[part 1 of 12: packages /VehicleProject/ECU to /E40_Platform_System_SystemPackage/Components]
AUTOSAR XML (schema 4-2-1)
standard types defined: uint8, uint16, UInt16, uint32, UInt32, sint32, boolean, Boolean, SInt32, UInt8, sint8, SInt8, sint16, SInt16
package /VehicleProject/ECU
  ecu instance IC
package /E40_Platform_System_SystemPackage
  composition sw component type E40_Platform_System_SoftwareArchitecture
    component E40_Platform_SystemCmp: type=E40_Platform_System
  system E40_Platform_System_System
    system mapping MAPPING
      sw-impl-mappings:
        64 x swc to impl mapping:
          ImplementationMapping1: component-implementation=IMPL_CBacklightCdd, component=SoftwareArchitecture.E40_Platform_SystemCmp.CBacklightCdd
          ImplementationMapping2: component-implementation=IMPL_IoHwAb, component=SoftwareArchitecture.E40_Platform_SystemCmp.IoHwAb
          ImplementationMapping3: component-implementation=IMPL_CCDD_BswFit, component=SoftwareArchitecture.E40_Platform_SystemCmp.CCDD_BswFit
          ImplementationMapping4: component-implementation=IMPL_EcuMExt, component=SoftwareArchitecture.E40_Platform_SystemCmp.EcuMExt
          ImplementationMapping5: component-implementation=IMPL_EcuAppM, component=SoftwareArchitecture.E40_Platform_SystemCmp.EcuAppM
          ImplementationMapping6: component-implementation=IMPL_CCDD_EcuBatteryM, component=SoftwareArchitecture.E40_Platform_SystemCmp.CCDD_EcuBatteryM
          ImplementationMapping7: component-implementation=IMPL_CCDD_EcuPowerM, component=SoftwareArchitecture.E40_Platform_SystemCmp.CCDD_EcuPowerM
          ImplementationMapping8: component-implementation=IMPL_CComAbsCtrl, component=SoftwareArchitecture.E40_Platform_SystemCmp.CComAbsCtrl
          ImplementationMapping9: component-implementation=IMPL_ComMExt, component=SoftwareArchitecture.E40_Platform_SystemCmp.ComMExt
          ImplementationMapping10: component-implementation=IMPL_CComAbsMdl, component=SoftwareArchitecture.E40_Platform_SystemCmp.CComAbsMdl
          ImplementationMapping11: component-implementation=IMPL_MemAbstractMdl, component=SoftwareArchitecture.E40_Platform_SystemCmp.MemAbstractMdl
          ImplementationMapping12: component-implementation=IMPL_CComAbsMdlSafe, component=SoftwareArchitecture.E40_Platform_SystemCmp.CComAbsMdlSafe
          ImplementationMapping13: component-implementation=IMPL_Ctrl_Illumination, component=SoftwareArchitecture.E40_Platform_SystemCmp.Ctrl_Illumination
          ImplementationMapping14: component-implementation=IMPL_Mdl_Dim, component=SoftwareArchitecture.E40_Platform_SystemCmp.Mdl_Dim
          ImplementationMapping15: component-implementation=IMPL_Ctrl_WSS, component=SoftwareArchitecture.E40_Platform_SystemCmp.Ctrl_WSS
          ImplementationMapping16: component-implementation=IMPL_NvMExt, component=SoftwareArchitecture.E40_Platform_SystemCmp.NvMExt
          ImplementationMapping17: component-implementation=IMPL_TmExt, component=SoftwareArchitecture.E40_Platform_SystemCmp.TmExt
          ImplementationMapping18: component-implementation=IMPL_CWarnMsg_Core_Observer, component=SoftwareArchitecture.E40_Platform_SystemCmp.CWarnMsg_Core_Observer
          ImplementationMapping19: component-implementation=IMPL_Ctrl_warning, component=SoftwareArchitecture.E40_Platform_SystemCmp.Ctrl_warning
          ImplementationMapping20: component-implementation=IMPL_UclProxyCdd, component=SoftwareArchitecture.E40_Platform_SystemCmp.UclProxyCdd
          ImplementationMapping21: component-implementation=IMPL_DmnMgr, component=SoftwareArchitecture.E40_Platform_SystemCmp.DmnMgr
          ImplementationMapping22: component-implementation=IMPL_CMeetCdd, component=SoftwareArchitecture.E40_Platform_SystemCmp.CMeetCdd
          ImplementationMapping23: component-implementation=IMPL_Mdl_Gear, component=SoftwareArchitecture.E40_Platform_SystemCmp.Mdl_Gear
          ImplementationMapping24: component-implementation=IMPL_View_Illumination, component=SoftwareArchitecture.E40_Platform_SystemCmp.View_Illumination
          ImplementationMapping25: component-implementation=IMPL_CView_Telltale, component=SoftwareArchitecture.E40_Platform_SystemCmp.CView_Telltale
          ImplementationMapping26: component-implementation=IMPL_Mdl_Airbag, component=SoftwareArchitecture.E40_Platform_SystemCmp.Mdl_Airbag
          ImplementationMapping27: component-implementation=IMPL_Mdl_TurnHazard, component=SoftwareArchitecture.E40_Platform_SystemCmp.Mdl_TurnHazard
          ImplementationMapping28: component-implementation=IMPL_CCtrl_Telltale, component=SoftwareArchitecture.E40_Platform_SystemCmp.CCtrl_Telltale
          ImplementationMapping29: component-implementation=IMPL_FastGaugeAdapter, component=SoftwareArchitecture.E40_Platform_SystemCmp.FastGaugeAdapter
          ImplementationMapping30: component-implementation=IMPL_View_Speed, component=SoftwareArchitecture.E40_Platform_SystemCmp.View_Speed
          ImplementationMapping31: component-implementation=IMPL_Mdl_Speed, component=SoftwareArchitecture.E40_Platform_SystemCmp.Mdl_Speed
          ImplementationMapping32: component-implementation=IMPL_Mdl_Linear_Interpolation, component=SoftwareArchitecture.E40_Platform_SystemCmp.Mdl_Linear_Interpolation
          ImplementationMapping33: component-implementation=IMPL_Mdl_Tacho, component=SoftwareArchitecture.E40_Platform_SystemCmp.Mdl_Tacho
          ImplementationMapping34: component-implementation=IMPL_SlowGaugeAdapter, component=SoftwareArchitecture.E40_Platform_SystemCmp.SlowGaugeAdapter
          ImplementationMapping35: component-implementation=IMPL_CUpdateCdd, component=SoftwareArchitecture.E40_Platform_SystemCmp.CUpdateCdd
          ImplementationMapping36: component-implementation=IMPL_DltExt, component=SoftwareArchitecture.E40_Platform_SystemCmp.DltExt
          ImplementationMapping37: component-implementation=IMPL_Mdl_wAirbag, component=SoftwareArchitecture.E40_Platform_SystemCmp.Mdl_wAirbag
          ImplementationMapping38: component-implementation=IMPL_Mdl_wFuelLidOpen, component=SoftwareArchitecture.E40_Platform_SystemCmp.Mdl_wFuelLidOpen
          ImplementationMapping39: component-implementation=IMPL_WarnMsg_Core_TmrSupport, component=SoftwareArchitecture.E40_Platform_SystemCmp.WarnMsg_Core_TmrSupport
          ImplementationMapping40: component-implementation=IMPL_DcmApp, component=SoftwareArchitecture.E40_Platform_SystemCmp.DcmApp
          ImplementationMapping41: component-implementation=IMPL_DemApp, component=SoftwareArchitecture.E40_Platform_SystemCmp.DemApp
          ImplementationMapping42: component-implementation=IMPL_DemExt, component=SoftwareArchitecture.E40_Platform_SystemCmp.DemExt
          ImplementationMapping43: component-implementation=IMPL_CDisplayCdd, component=SoftwareArchitecture.E40_Platform_SystemCmp.CDisplayCdd
          ImplementationMapping44: component-implementation=IMPL_CFltM, component=SoftwareArchitecture.E40_Platform_SystemCmp.CFltM
          ImplementationMapping45: component-implementation=IMPL_CRstM, component=SoftwareArchitecture.E40_Platform_SystemCmp.CRstM
          ImplementationMapping46: component-implementation=IMPL_Dlt, component=SoftwareArchitecture.E40_Platform_SystemCmp.Dlt
          ImplementationMapping47: component-implementation=IMPL_CFltMExt, component=SoftwareArchitecture.E40_Platform_SystemCmp.CFltMExt
          ImplementationMapping48: component-implementation=IMPL_GdtCdd, component=SoftwareArchitecture.E40_Platform_SystemCmp.GdtCdd
          ImplementationMapping49: component-implementation=IMPL_CIoExp, component=SoftwareArchitecture.E40_Platform_SystemCmp.CIoExp
          ImplementationMapping50: component-implementation=IMPL_CPmicCdd, component=SoftwareArchitecture.E40_Platform_SystemCmp.CPmicCdd
          ImplementationMapping51: component-implementation=IMPL_RtcCdd, component=SoftwareArchitecture.E40_Platform_SystemCmp.RtcCdd
          ImplementationMapping52: component-implementation=IMPL_SafeNvM, component=SoftwareArchitecture.E40_Platform_SystemCmp.SafeNvM
          ImplementationMapping53: component-implementation=IMPL_CSigCdd, component=SoftwareArchitecture.E40_Platform_SystemCmp.CSigCdd
          ImplementationMapping54: component-implementation=IMPL_CSwcDispMonSf, component=SoftwareArchitecture.E40_Platform_SystemCmp.CSwcDispMonSf
          ImplementationMapping55: component-implementation=IMPL_CSndCdd, component=SoftwareArchitecture.E40_Platform_SystemCmp.CSndCdd
          ImplementationMapping56: component-implementation=IMPL_CorTst, component=SoftwareArchitecture.E40_Platform_SystemCmp.CorTst
          ImplementationMapping57: component-implementation=IMPL_FlsTst, component=SoftwareArchitecture.E40_Platform_SystemCmp.FlsTst
          ImplementationMapping58: component-implementation=IMPL_RamTst, component=SoftwareArchitecture.E40_Platform_SystemCmp.RamTst
          ImplementationMapping59: component-implementation=IMPL_SysTst, component=SoftwareArchitecture.E40_Platform_SystemCmp.SysTst
          ImplementationMapping60: component-implementation=IMPL_CCDD_FitManager, component=SoftwareArchitecture.E40_Platform_SystemCmp.CCDD_FitManager
          ImplementationMapping61: component-implementation=IMPL_CCDD_McuFit, component=SoftwareArchitecture.E40_Platform_SystemCmp.CCDD_McuFit
          ImplementationMapping62: component-implementation=IMPL_ComCallout, component=SoftwareArchitecture.E40_Platform_SystemCmp.ComCallout
          ImplementationMapping63: component-implementation=IMPL_DcmExt, component=SoftwareArchitecture.E40_Platform_SystemCmp.DcmExt
          ImplementationMapping64: component-implementation=IMPL_Mdl_SafetyAdapter, component=SoftwareArchitecture.E40_Platform_SystemCmp.Mdl_SafetyAdapter
      sw-mappings:
        swc to ecu mapping SwcToEcuMapping: ecu-instance=IC
    root-software-compositions:
      root sw composition prototype SoftwareArchitecture: software-composition=E40_Platform_System
package /E40_Platform_System_SystemPackage/Components
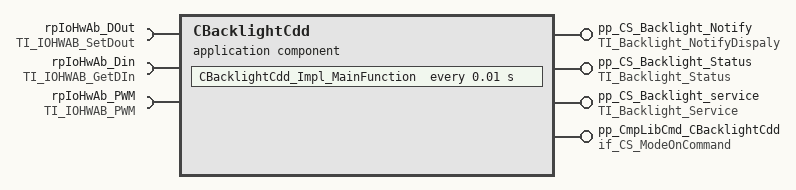
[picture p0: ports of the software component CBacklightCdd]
  application sw component type CBacklightCdd
    4 x provide port:
      pp_CS_Backlight_Notify: server-com-spec{operation=NotifyDisplayPowerState, queue-length=1}, provided-interface=TI_Backlight_NotifyDispaly
      pp_CS_Backlight_Status: server-com-spec{operation=TI_Backlight_Status/GetStatus, queue-length=1}, provided-interface=TI_Backlight_Status
      pp_CS_Backlight_service: provided-interface=TI_Backlight_Service
        provided-com-specs:
          operation=GetBrightnessValue, queue-length=1
          operation=GetThermalValue, queue-length=1
          operation=SetBrightnessValue, queue-length=1
      pp_CmpLibCmd_CBacklightCdd: server-com-spec{operation=Impl_OnCommand, queue-length=1}, provided-interface=if_CS_ModeOnCommand
    require port rpIoHwAb_DOut: required-interface=TI_IOHWAB_SetDout
    require port rpIoHwAb_Din: required-interface=TI_IOHWAB_GetDIn
    require port rpIoHwAb_PWM: required-interface=TI_IOHWAB_PWM
    behavior IB_CBacklightCdd
      operation invoked event OIE_pp_CS_Backlight_service_CBacklightCdd_GetBrightnessValueTrigByGetBrightnessValue: start-on-event=CBacklightCdd_GetBrightnessValue, operation=pp_CS_Backlight_service.GetBrightnessValue
      operation invoked event OIE_pp_CS_Backlight_Status_CBacklightCdd_GetStatusTrigByGetStatus: start-on-event=CBacklightCdd_GetStatus, operation=pp_CS_Backlight_Status.GetStatus
      operation invoked event OIE_pp_CS_Backlight_service_CBacklightCdd_GetThermalValueTrigByGetThermalValue: start-on-event=CBacklightCdd_GetThermalValue, operation=pp_CS_Backlight_service.GetThermalValue
      timing event TECBacklightCdd_Impl_MainFunction: start-on-event=CBacklightCdd_Impl_MainFunction, period=0.01
      operation invoked event OIE_pp_CmpLibCmd_CBacklightCdd_CBacklightCdd_Impl_OnCommandTrigByImpl_OnCommand: start-on-event=CBacklightCdd_Impl_OnCommand, operation=pp_CmpLibCmd_CBacklightCdd.Impl_OnCommand
      operation invoked event OIE_pp_CS_Backlight_Notify_CBacklightCdd_NotifyDisplayPowerStateTrigByNotifyDisplayPowerState: start-on-event=CBacklightCdd_NotifyDisplayPowerState, operation=pp_CS_Backlight_Notify.NotifyDisplayPowerState
      operation invoked event OIE_pp_CS_Backlight_service_CBacklightCdd_SetBrightnessValueTrigBySetBrightnessValue: start-on-event=CBacklightCdd_SetBrightnessValue, operation=pp_CS_Backlight_service.SetBrightnessValue
      port-api-options:
        enable-take-address=false, indirect-api=false, port=pp_CS_Backlight_Notify
        enable-take-address=false, indirect-api=false, port=pp_CS_Backlight_Status
        enable-take-address=false, indirect-api=false, port=pp_CS_Backlight_service
        enable-take-address=false, indirect-api=false, port=pp_CmpLibCmd_CBacklightCdd
        enable-take-address=false, indirect-api=false, port=CBacklightCdd/rpIoHwAb_DOut
        enable-take-address=false, indirect-api=false, port=CBacklightCdd/rpIoHwAb_Din
        enable-take-address=false, indirect-api=false, port=CBacklightCdd/rpIoHwAb_PWM
      7 x runnable, all with can-be-invoked-concurrently=true:
        CBacklightCdd_GetBrightnessValue
          9 x sync call, all with timeout=0.0:
            OA_rpIoHwAb_DOut_SetOutputGroup: operation=rpIoHwAb_DOut.SetOutputGroup
            OA_rpIoHwAb_DOut_SetOutputPin: operation=rpIoHwAb_DOut.SetOutputPin
            OA_rpIoHwAb_Din_GetAsyncRawInput: operation=rpIoHwAb_Din.GetAsyncRawInput
            OA_rpIoHwAb_Din_GetProcessedInput: operation=rpIoHwAb_Din.GetProcessedInput
            OA_rpIoHwAb_Din_GetSyncRawInput: operation=rpIoHwAb_Din.GetSyncRawInput
            OA_rpIoHwAb_Din_GetInputGroup: operation=rpIoHwAb_Din.GetInputGroup
            OA_rpIoHwAb_PWM_PwmSetDuty: operation=rpIoHwAb_PWM.PwmSetDuty
            OA_rpIoHwAb_PWM_PwmSetDutyAndPeriod: operation=rpIoHwAb_PWM.PwmSetDutyAndPeriod
            OA_rpIoHwAb_PWM_PwmSetIdeal: operation=rpIoHwAb_PWM.PwmSetIdeal
        CBacklightCdd_GetStatus
          9 x sync call, all with timeout=0.0:
            OA_rpIoHwAb_DOut_SetOutputGroup: operation=rpIoHwAb_DOut.SetOutputGroup
            OA_rpIoHwAb_DOut_SetOutputPin: operation=rpIoHwAb_DOut.SetOutputPin
            OA_rpIoHwAb_Din_GetAsyncRawInput: operation=rpIoHwAb_Din.GetAsyncRawInput
            OA_rpIoHwAb_Din_GetProcessedInput: operation=rpIoHwAb_Din.GetProcessedInput
            OA_rpIoHwAb_Din_GetSyncRawInput: operation=rpIoHwAb_Din.GetSyncRawInput
            OA_rpIoHwAb_Din_GetInputGroup: operation=rpIoHwAb_Din.GetInputGroup
            OA_rpIoHwAb_PWM_PwmSetDuty: operation=rpIoHwAb_PWM.PwmSetDuty
            OA_rpIoHwAb_PWM_PwmSetDutyAndPeriod: operation=rpIoHwAb_PWM.PwmSetDutyAndPeriod
            OA_rpIoHwAb_PWM_PwmSetIdeal: operation=rpIoHwAb_PWM.PwmSetIdeal
        CBacklightCdd_GetThermalValue
          9 x sync call, all with timeout=0.0:
            OA_rpIoHwAb_DOut_SetOutputGroup: operation=rpIoHwAb_DOut.SetOutputGroup
            OA_rpIoHwAb_DOut_SetOutputPin: operation=rpIoHwAb_DOut.SetOutputPin
            OA_rpIoHwAb_Din_GetAsyncRawInput: operation=rpIoHwAb_Din.GetAsyncRawInput
            OA_rpIoHwAb_Din_GetProcessedInput: operation=rpIoHwAb_Din.GetProcessedInput
            OA_rpIoHwAb_Din_GetSyncRawInput: operation=rpIoHwAb_Din.GetSyncRawInput
            OA_rpIoHwAb_Din_GetInputGroup: operation=rpIoHwAb_Din.GetInputGroup
            OA_rpIoHwAb_PWM_PwmSetDuty: operation=rpIoHwAb_PWM.PwmSetDuty
            OA_rpIoHwAb_PWM_PwmSetDutyAndPeriod: operation=rpIoHwAb_PWM.PwmSetDutyAndPeriod
            OA_rpIoHwAb_PWM_PwmSetIdeal: operation=rpIoHwAb_PWM.PwmSetIdeal
        CBacklightCdd_Impl_MainFunction
          9 x sync call, all with timeout=0.0:
            OA_rpIoHwAb_DOut_SetOutputGroup: operation=rpIoHwAb_DOut.SetOutputGroup
            OA_rpIoHwAb_DOut_SetOutputPin: operation=rpIoHwAb_DOut.SetOutputPin
            OA_rpIoHwAb_Din_GetAsyncRawInput: operation=rpIoHwAb_Din.GetAsyncRawInput
            OA_rpIoHwAb_Din_GetProcessedInput: operation=rpIoHwAb_Din.GetProcessedInput
            OA_rpIoHwAb_Din_GetSyncRawInput: operation=rpIoHwAb_Din.GetSyncRawInput
            OA_rpIoHwAb_Din_GetInputGroup: operation=rpIoHwAb_Din.GetInputGroup
            OA_rpIoHwAb_PWM_PwmSetDuty: operation=rpIoHwAb_PWM.PwmSetDuty
            OA_rpIoHwAb_PWM_PwmSetDutyAndPeriod: operation=rpIoHwAb_PWM.PwmSetDutyAndPeriod
            OA_rpIoHwAb_PWM_PwmSetIdeal: operation=rpIoHwAb_PWM.PwmSetIdeal
        CBacklightCdd_Impl_OnCommand
          9 x sync call, all with timeout=0.0:
            OA_rpIoHwAb_DOut_SetOutputGroup: operation=rpIoHwAb_DOut.SetOutputGroup
            OA_rpIoHwAb_DOut_SetOutputPin: operation=rpIoHwAb_DOut.SetOutputPin
            OA_rpIoHwAb_Din_GetAsyncRawInput: operation=rpIoHwAb_Din.GetAsyncRawInput
            OA_rpIoHwAb_Din_GetProcessedInput: operation=rpIoHwAb_Din.GetProcessedInput
            OA_rpIoHwAb_Din_GetSyncRawInput: operation=rpIoHwAb_Din.GetSyncRawInput
            OA_rpIoHwAb_Din_GetInputGroup: operation=rpIoHwAb_Din.GetInputGroup
            OA_rpIoHwAb_PWM_PwmSetDuty: operation=rpIoHwAb_PWM.PwmSetDuty
            OA_rpIoHwAb_PWM_PwmSetDutyAndPeriod: operation=rpIoHwAb_PWM.PwmSetDutyAndPeriod
            OA_rpIoHwAb_PWM_PwmSetIdeal: operation=rpIoHwAb_PWM.PwmSetIdeal
        CBacklightCdd_NotifyDisplayPowerState
          9 x sync call, all with timeout=0.0:
            OA_rpIoHwAb_DOut_SetOutputGroup: operation=rpIoHwAb_DOut.SetOutputGroup
            OA_rpIoHwAb_DOut_SetOutputPin: operation=rpIoHwAb_DOut.SetOutputPin
            OA_rpIoHwAb_Din_GetAsyncRawInput: operation=rpIoHwAb_Din.GetAsyncRawInput
            OA_rpIoHwAb_Din_GetProcessedInput: operation=rpIoHwAb_Din.GetProcessedInput
            OA_rpIoHwAb_Din_GetSyncRawInput: operation=rpIoHwAb_Din.GetSyncRawInput
            OA_rpIoHwAb_Din_GetInputGroup: operation=rpIoHwAb_Din.GetInputGroup
            OA_rpIoHwAb_PWM_PwmSetDuty: operation=rpIoHwAb_PWM.PwmSetDuty
            OA_rpIoHwAb_PWM_PwmSetDutyAndPeriod: operation=rpIoHwAb_PWM.PwmSetDutyAndPeriod
            OA_rpIoHwAb_PWM_PwmSetIdeal: operation=rpIoHwAb_PWM.PwmSetIdeal
        CBacklightCdd_SetBrightnessValue
          9 x sync call, all with timeout=0.0:
            OA_rpIoHwAb_DOut_SetOutputGroup: operation=rpIoHwAb_DOut.SetOutputGroup
            OA_rpIoHwAb_DOut_SetOutputPin: operation=rpIoHwAb_DOut.SetOutputPin
            OA_rpIoHwAb_Din_GetAsyncRawInput: operation=rpIoHwAb_Din.GetAsyncRawInput
            OA_rpIoHwAb_Din_GetProcessedInput: operation=rpIoHwAb_Din.GetProcessedInput
            OA_rpIoHwAb_Din_GetSyncRawInput: operation=rpIoHwAb_Din.GetSyncRawInput
            OA_rpIoHwAb_Din_GetInputGroup: operation=rpIoHwAb_Din.GetInputGroup
            OA_rpIoHwAb_PWM_PwmSetDuty: operation=rpIoHwAb_PWM.PwmSetDuty
            OA_rpIoHwAb_PWM_PwmSetDutyAndPeriod: operation=rpIoHwAb_PWM.PwmSetDutyAndPeriod
            OA_rpIoHwAb_PWM_PwmSetIdeal: operation=rpIoHwAb_PWM.PwmSetIdeal
  swc implementation IMPL_CBacklightCdd: programming-language=C, behavior=IB_CBacklightCdd
    code-descriptors:
      code CodeDescriptor
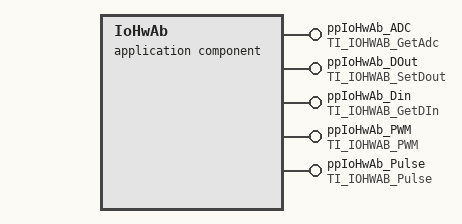
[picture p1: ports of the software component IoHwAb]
  application sw component type IoHwAb
    5 x provide port:
      ppIoHwAb_ADC: provided-interface=TI_IOHWAB_GetAdc
        provided-com-specs:
          operation=GetAsyncRawAdc, queue-length=1
          operation=GetProcessedAdc, queue-length=1
          operation=GetSyncRawAdc, queue-length=1
      ppIoHwAb_DOut: provided-com-specs=[{operation=SetOutputGroup, queue-length=1}, {operation=SetOutputPin, queue-length=1}], provided-interface=TI_IOHWAB_SetDout
      ppIoHwAb_Din: provided-interface=TI_IOHWAB_GetDIn
        provided-com-specs:
          operation=GetAsyncRawInput, queue-length=1
          operation=GetInputGroup, queue-length=1
          operation=GetProcessedInput, queue-length=1
          operation=GetSyncRawInput, queue-length=1
      ppIoHwAb_PWM: provided-interface=TI_IOHWAB_PWM
        provided-com-specs:
          operation=PwmSetDuty, queue-length=1
          operation=PwmSetDutyAndPeriod, queue-length=1
          operation=PwmSetIdeal, queue-length=1
      ppIoHwAb_Pulse: provided-interface=TI_IOHWAB_Pulse
        provided-com-specs:
          operation=GetCurrentSignalStatus_PulseInput, queue-length=1
          operation=GetCurrentSpeed_PulseInput, queue-length=1
          operation=GetRollingCount_PulseInput, queue-length=1
          operation=ResetRollingCount_PulseInput, queue-length=1
          operation=Start_Signal_Measurement_PulseInput, queue-length=1
          operation=Stop_Signal_Measurement_PulseInput, queue-length=1
          operation=Update_CalibParam_PulseInput, queue-length=1
    behavior IB_IoHwAb
      10 x operation invoked event:
        OIE_ppIoHwAb_ADC_IoHwAb_GetAsyncRawAdcTrigByGetAsyncRawAdc: start-on-event=IoHwAb_GetAsyncRawAdc, operation=ppIoHwAb_ADC.GetAsyncRawAdc
        OIE_ppIoHwAb_Din_IoHwAb_GetAsyncRawInputTrigByGetAsyncRawInput: start-on-event=IoHwAb_GetAsyncRawInput, operation=ppIoHwAb_Din.GetAsyncRawInput
        OIE_ppIoHwAb_Pulse_IoHwAb_GetCurrentSignalStatus_PulseInputTrigByGetCurrentSignalStatus_PulseInput: start-on-event=IoHwAb_GetCurrentSignalStatus_PulseInput, operation=ppIoHwAb_Pulse.GetCurrentSignalStatus_PulseInput
        OIE_ppIoHwAb_Pulse_IoHwAb_GetCurrentSpeed_PulseInputTrigByGetCurrentSpeed_PulseInput: start-on-event=IoHwAb_GetCurrentSpeed_PulseInput, operation=ppIoHwAb_Pulse.GetCurrentSpeed_PulseInput
        OIE_ppIoHwAb_Din_IoHwAb_GetInputGroupTrigByGetInputGroup: start-on-event=IoHwAb_GetInputGroup, operation=ppIoHwAb_Din.GetInputGroup
        OIE_ppIoHwAb_ADC_IoHwAb_GetProcessedAdcTrigByGetProcessedAdc: start-on-event=IoHwAb_GetProcessedAdc, operation=ppIoHwAb_ADC.GetProcessedAdc
        OIE_ppIoHwAb_Din_IoHwAb_GetProcessedInputTrigByGetProcessedInput: start-on-event=IoHwAb_GetProcessedInput, operation=ppIoHwAb_Din.GetProcessedInput
        OIE_ppIoHwAb_Pulse_IoHwAb_GetRollingCount_PulseInputTrigByGetRollingCount_PulseInput: start-on-event=IoHwAb_GetRollingCount_PulseInput, operation=ppIoHwAb_Pulse.GetRollingCount_PulseInput
        OIE_ppIoHwAb_ADC_IoHwAb_GetSyncRawAdcTrigByGetSyncRawAdc: start-on-event=IoHwAb_GetSyncRawAdc, operation=ppIoHwAb_ADC.GetSyncRawAdc
        OIE_ppIoHwAb_Din_IoHwAb_GetSyncRawInputTrigByGetSyncRawInput: start-on-event=IoHwAb_GetSyncRawInput, operation=ppIoHwAb_Din.GetSyncRawInput
      5 x timing event:
        TEIoHwAb_MainFunction: start-on-event=IoHwAb_MainFunction, period=0.01
        TEIoHwAb_OsTask_SafeBsw_Task_10ms: start-on-event=IoHwAb_OsTask_SafeBsw_Task_10ms, period=0.01
        TEIoHwAb_OsTask_SafeBsw_WdgM_CheckPoint_10ms: start-on-event=IoHwAb_OsTask_SafeBsw_WdgM_CheckPoint_10ms, period=0.01
        TEIoHwAb_OsTask_SafeBsw_WdgM_CheckPoint_20ms: start-on-event=IoHwAb_OsTask_SafeBsw_WdgM_CheckPoint_20ms, period=0.02
        TEIoHwAb_OsTask_SafeBsw_WdgM_CheckPoint_30ms: start-on-event=IoHwAb_OsTask_SafeBsw_WdgM_CheckPoint_30ms, period=0.03
      9 x operation invoked event:
        OIE_ppIoHwAb_PWM_IoHwAb_PwmSetDutyTrigByPwmSetDuty: start-on-event=IoHwAb_PwmSetDuty, operation=ppIoHwAb_PWM.PwmSetDuty
        OIE_ppIoHwAb_PWM_IoHwAb_PwmSetDutyAndPeriodTrigByPwmSetDutyAndPeriod: start-on-event=IoHwAb_PwmSetDutyAndPeriod, operation=ppIoHwAb_PWM.PwmSetDutyAndPeriod
        OIE_ppIoHwAb_PWM_IoHwAb_PwmSetIdealTrigByPwmSetIdeal: start-on-event=IoHwAb_PwmSetIdeal, operation=ppIoHwAb_PWM.PwmSetIdeal
        OIE_ppIoHwAb_Pulse_IoHwAb_ResetRollingCount_PulseInputTrigByResetRollingCount_PulseInput: start-on-event=IoHwAb_ResetRollingCount_PulseInput, operation=ppIoHwAb_Pulse.ResetRollingCount_PulseInput
        OIE_ppIoHwAb_DOut_IoHwAb_SetOutputGroupTrigBySetOutputGroup: start-on-event=IoHwAb_SetOutputGroup, operation=ppIoHwAb_DOut.SetOutputGroup
        OIE_ppIoHwAb_DOut_IoHwAb_SetOutputPinTrigBySetOutputPin: start-on-event=IoHwAb_SetOutputPin, operation=ppIoHwAb_DOut.SetOutputPin
        OIE_ppIoHwAb_Pulse_IoHwAb_Start_Signal_Measurement_PulseInputTrigByStart_Signal_Measurement_PulseInput: start-on-event=IoHwAb_Start_Signal_Measurement_PulseInput, operation=ppIoHwAb_Pulse.Start_Signal_Measurement_PulseInput
        OIE_ppIoHwAb_Pulse_IoHwAb_Stop_Signal_Measurement_PulseInputTrigByStop_Signal_Measurement_PulseInput: start-on-event=IoHwAb_Stop_Signal_Measurement_PulseInput, operation=ppIoHwAb_Pulse.Stop_Signal_Measurement_PulseInput
        OIE_ppIoHwAb_Pulse_IoHwAb_Update_CalibParam_PulseInputTrigByUpdate_CalibParam_PulseInput: start-on-event=IoHwAb_Update_CalibParam_PulseInput, operation=ppIoHwAb_Pulse.Update_CalibParam_PulseInput
      port-api-options:
        enable-take-address=false, indirect-api=false, port=ppIoHwAb_ADC
        enable-take-address=false, indirect-api=false, port=ppIoHwAb_DOut
        enable-take-address=false, indirect-api=false, port=ppIoHwAb_Din
        enable-take-address=false, indirect-api=false, port=ppIoHwAb_PWM
        enable-take-address=false, indirect-api=false, port=ppIoHwAb_Pulse
      24 x runnable, all with can-be-invoked-concurrently=true:
        IoHwAb_GetAsyncRawAdc
        IoHwAb_GetAsyncRawInput
        IoHwAb_GetCurrentSignalStatus_PulseInput
        IoHwAb_GetCurrentSpeed_PulseInput
        IoHwAb_GetInputGroup
        IoHwAb_GetProcessedAdc
        IoHwAb_GetProcessedInput
        IoHwAb_GetRollingCount_PulseInput
        IoHwAb_GetSyncRawAdc
        IoHwAb_GetSyncRawInput
        IoHwAb_MainFunction
        IoHwAb_OsTask_SafeBsw_Task_10ms
        IoHwAb_OsTask_SafeBsw_WdgM_CheckPoint_10ms
        IoHwAb_OsTask_SafeBsw_WdgM_CheckPoint_20ms
        IoHwAb_OsTask_SafeBsw_WdgM_CheckPoint_30ms
        IoHwAb_PwmSetDuty
        IoHwAb_PwmSetDutyAndPeriod
        IoHwAb_PwmSetIdeal
        IoHwAb_ResetRollingCount_PulseInput
        IoHwAb_SetOutputGroup
        IoHwAb_SetOutputPin
        IoHwAb_Start_Signal_Measurement_PulseInput
        IoHwAb_Stop_Signal_Measurement_PulseInput
        IoHwAb_Update_CalibParam_PulseInput
  swc implementation IMPL_IoHwAb: programming-language=C, behavior=IB_IoHwAb
    code-descriptors:
      code CodeDescriptor
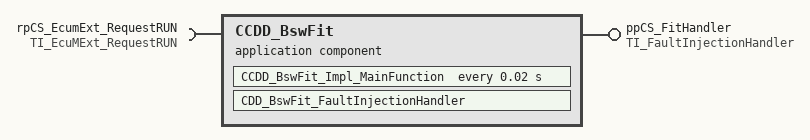
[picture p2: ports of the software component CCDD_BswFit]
  application sw component type CCDD_BswFit
    provide port ppCS_FitHandler: server-com-spec{operation=FaultInjectionHandler, queue-length=1}, provided-interface=TI_FaultInjectionHandler
    require port rpCS_EcumExt_RequestRUN: required-interface=TI_EcuMExt_RequestRUN
    behavior IB_CCDD_BswFit
      operation invoked event OIE_ppCS_FitHandler_CDD_BswFit_FaultInjectionHandlerTrigByFaultInjectionHandler: start-on-event=CDD_BswFit_FaultInjectionHandler, operation=ppCS_FitHandler.FaultInjectionHandler
      timing event TECCDD_BswFit_Impl_MainFunction: start-on-event=CCDD_BswFit_Impl_MainFunction, period=0.02
      port-api-options:
        enable-take-address=false, indirect-api=false, port=CCDD_BswFit/ppCS_FitHandler
        enable-take-address=false, indirect-api=false, port=CCDD_BswFit/rpCS_EcumExt_RequestRUN
      runnable CDD_BswFit_FaultInjectionHandler: can-be-invoked-concurrently=true
      runnable CCDD_BswFit_Impl_MainFunction: can-be-invoked-concurrently=true
        sync call OA_rpCS_EcumExt_RequestRUN_RequestRUN: operation=rpCS_EcumExt_RequestRUN.RequestRUN, timeout=0.0
  swc implementation IMPL_CCDD_BswFit: programming-language=C, behavior=IB_CCDD_BswFit
    code-descriptors:
      code CodeDescriptor
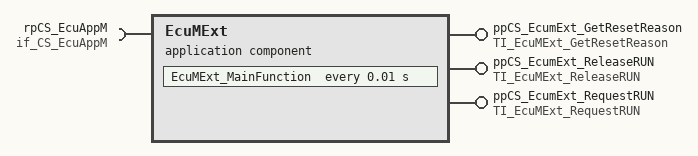
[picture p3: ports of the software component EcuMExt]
  application sw component type EcuMExt
    provide port ppCS_EcumExt_GetResetReason: server-com-spec{operation=GetResetReason, queue-length=1}, provided-interface=TI_EcuMExt_GetResetReason
    provide port ppCS_EcumExt_ReleaseRUN: server-com-spec{operation=ReleaseRUN, queue-length=1}, provided-interface=TI_EcuMExt_ReleaseRUN
    provide port ppCS_EcumExt_RequestRUN: server-com-spec{operation=RequestRUN, queue-length=1}, provided-interface=TI_EcuMExt_RequestRUN
    require port rpCS_EcuAppM: required-interface=if_CS_EcuAppM
    behavior IB_EcuMExt
      operation invoked event OIE_ppCS_EcumExt_GetResetReason_EcuMExt_GetResetReasonTrigByGetResetReason: start-on-event=EcuMExt_GetResetReason, operation=ppCS_EcumExt_GetResetReason.GetResetReason
      timing event TEEcuMExt_MainFunction: start-on-event=EcuMExt_MainFunction, period=0.01
      operation invoked event OIE_ppCS_EcumExt_ReleaseRUN_EcuMExt_ReleaseRUNTrigByReleaseRUN: start-on-event=EcuMExt_ReleaseRUN, operation=ppCS_EcumExt_ReleaseRUN.ReleaseRUN
      operation invoked event OIE_ppCS_EcumExt_RequestRUN_EcuMExt_RequestRUNTrigByRequestRUN: start-on-event=EcuMExt_RequestRUN, operation=ppCS_EcumExt_RequestRUN.RequestRUN
      port-api-options:
        enable-take-address=false, indirect-api=false, port=ppCS_EcumExt_GetResetReason
        enable-take-address=false, indirect-api=false, port=ppCS_EcumExt_ReleaseRUN
        enable-take-address=false, indirect-api=false, port=ppCS_EcumExt_RequestRUN
        enable-take-address=false, indirect-api=false, port=rpCS_EcuAppM
      4 x runnable, all with can-be-invoked-concurrently=true:
        EcuMExt_GetResetReason
          sync call OA_rpCS_EcuAppM_Init: operation=rpCS_EcuAppM.Init, timeout=0.0
          sync call OA_rpCS_EcuAppM_EcuAppM_SetWakeupSources: operation=rpCS_EcuAppM.EcuAppM_SetWakeupSources, timeout=0.0
        EcuMExt_MainFunction
          sync call OA_rpCS_EcuAppM_Init: operation=rpCS_EcuAppM.Init, timeout=0.0
          sync call OA_rpCS_EcuAppM_EcuAppM_SetWakeupSources: operation=rpCS_EcuAppM.EcuAppM_SetWakeupSources, timeout=0.0
        EcuMExt_ReleaseRUN
          sync call OA_rpCS_EcuAppM_Init: operation=rpCS_EcuAppM.Init, timeout=0.0
          sync call OA_rpCS_EcuAppM_EcuAppM_SetWakeupSources: operation=rpCS_EcuAppM.EcuAppM_SetWakeupSources, timeout=0.0
        EcuMExt_RequestRUN
          sync call OA_rpCS_EcuAppM_Init: operation=rpCS_EcuAppM.Init, timeout=0.0
          sync call OA_rpCS_EcuAppM_EcuAppM_SetWakeupSources: operation=rpCS_EcuAppM.EcuAppM_SetWakeupSources, timeout=0.0
  swc implementation IMPL_EcuMExt: programming-language=C, behavior=IB_EcuMExt
    code-descriptors:
      code CodeDescriptor
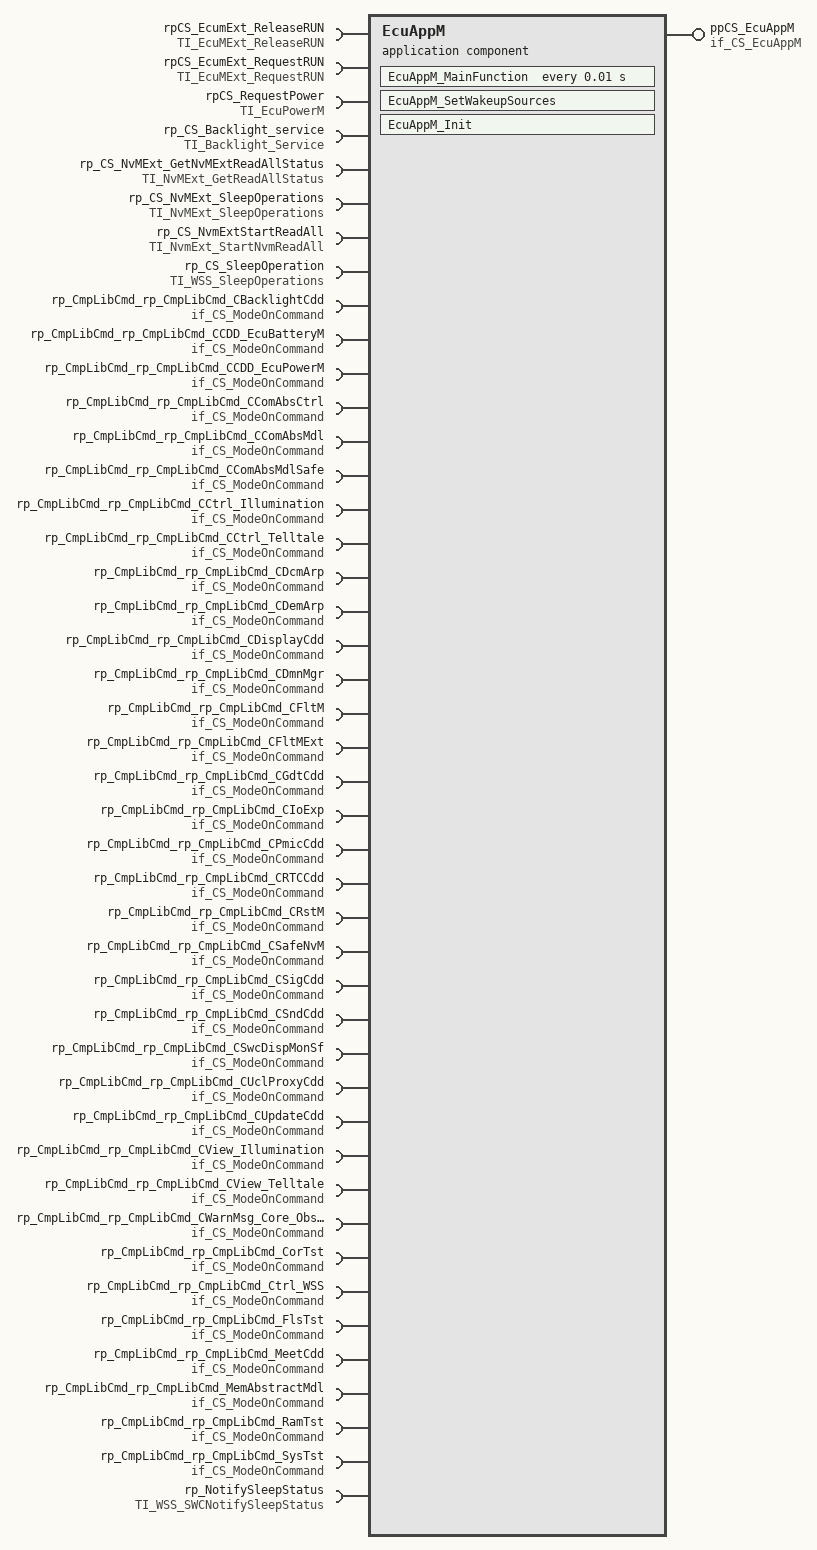
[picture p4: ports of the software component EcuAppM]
  application sw component type EcuAppM
    provide port ppCS_EcuAppM: provided-com-specs=[{operation=EcuAppM_SetWakeupSources, queue-length=1}, {operation=if_CS_EcuAppM/Init, queue-length=1}], provided-interface=if_CS_EcuAppM
    44 x require port:
      rpCS_EcumExt_ReleaseRUN: required-interface=TI_EcuMExt_ReleaseRUN
      rpCS_EcumExt_RequestRUN: required-interface=TI_EcuMExt_RequestRUN
      rpCS_RequestPower: required-interface=TI_EcuPowerM
      rp_CS_Backlight_service: required-interface=TI_Backlight_Service
      rp_CS_NvMExt_GetNvMExtReadAllStatus: required-interface=TI_NvMExt_GetReadAllStatus
      rp_CS_NvMExt_SleepOperations: required-interface=TI_NvMExt_SleepOperations
      rp_CS_NvmExtStartReadAll: required-interface=TI_NvmExt_StartNvmReadAll
      rp_CS_SleepOperation: required-interface=TI_WSS_SleepOperations
      rp_CmpLibCmd_rp_CmpLibCmd_CBacklightCdd: required-interface=if_CS_ModeOnCommand
      rp_CmpLibCmd_rp_CmpLibCmd_CCDD_EcuBatteryM: required-interface=if_CS_ModeOnCommand
      rp_CmpLibCmd_rp_CmpLibCmd_CCDD_EcuPowerM: required-interface=if_CS_ModeOnCommand
      rp_CmpLibCmd_rp_CmpLibCmd_CComAbsCtrl: required-interface=if_CS_ModeOnCommand
      rp_CmpLibCmd_rp_CmpLibCmd_CComAbsMdl: required-interface=if_CS_ModeOnCommand
      rp_CmpLibCmd_rp_CmpLibCmd_CComAbsMdlSafe: required-interface=if_CS_ModeOnCommand
      rp_CmpLibCmd_rp_CmpLibCmd_CCtrl_Illumination: required-interface=if_CS_ModeOnCommand
      rp_CmpLibCmd_rp_CmpLibCmd_CCtrl_Telltale: required-interface=if_CS_ModeOnCommand
      rp_CmpLibCmd_rp_CmpLibCmd_CDcmArp: required-interface=if_CS_ModeOnCommand
      rp_CmpLibCmd_rp_CmpLibCmd_CDemArp: required-interface=if_CS_ModeOnCommand
      rp_CmpLibCmd_rp_CmpLibCmd_CDisplayCdd: required-interface=if_CS_ModeOnCommand
      rp_CmpLibCmd_rp_CmpLibCmd_CDmnMgr: required-interface=if_CS_ModeOnCommand
      rp_CmpLibCmd_rp_CmpLibCmd_CFltM: required-interface=if_CS_ModeOnCommand
      rp_CmpLibCmd_rp_CmpLibCmd_CFltMExt: required-interface=if_CS_ModeOnCommand
      rp_CmpLibCmd_rp_CmpLibCmd_CGdtCdd: required-interface=if_CS_ModeOnCommand
      rp_CmpLibCmd_rp_CmpLibCmd_CIoExp: required-interface=if_CS_ModeOnCommand
      rp_CmpLibCmd_rp_CmpLibCmd_CPmicCdd: required-interface=if_CS_ModeOnCommand
      rp_CmpLibCmd_rp_CmpLibCmd_CRTCCdd: required-interface=if_CS_ModeOnCommand
      rp_CmpLibCmd_rp_CmpLibCmd_CRstM: required-interface=if_CS_ModeOnCommand
      rp_CmpLibCmd_rp_CmpLibCmd_CSafeNvM: required-interface=if_CS_ModeOnCommand
      rp_CmpLibCmd_rp_CmpLibCmd_CSigCdd: required-interface=if_CS_ModeOnCommand
      rp_CmpLibCmd_rp_CmpLibCmd_CSndCdd: required-interface=if_CS_ModeOnCommand
      rp_CmpLibCmd_rp_CmpLibCmd_CSwcDispMonSf: required-interface=if_CS_ModeOnCommand
      rp_CmpLibCmd_rp_CmpLibCmd_CUclProxyCdd: required-interface=if_CS_ModeOnCommand
      rp_CmpLibCmd_rp_CmpLibCmd_CUpdateCdd: required-interface=if_CS_ModeOnCommand
      rp_CmpLibCmd_rp_CmpLibCmd_CView_Illumination: required-interface=if_CS_ModeOnCommand
      rp_CmpLibCmd_rp_CmpLibCmd_CView_Telltale: required-interface=if_CS_ModeOnCommand
      rp_CmpLibCmd_rp_CmpLibCmd_CWarnMsg_Core_Observer: required-interface=if_CS_ModeOnCommand
      rp_CmpLibCmd_rp_CmpLibCmd_CorTst: required-interface=if_CS_ModeOnCommand
      rp_CmpLibCmd_rp_CmpLibCmd_Ctrl_WSS: required-interface=if_CS_ModeOnCommand
      rp_CmpLibCmd_rp_CmpLibCmd_FlsTst: required-interface=if_CS_ModeOnCommand
      rp_CmpLibCmd_rp_CmpLibCmd_MeetCdd: required-interface=if_CS_ModeOnCommand
      rp_CmpLibCmd_rp_CmpLibCmd_MemAbstractMdl: required-interface=if_CS_ModeOnCommand
      rp_CmpLibCmd_rp_CmpLibCmd_RamTst: required-interface=if_CS_ModeOnCommand
      rp_CmpLibCmd_rp_CmpLibCmd_SysTst: required-interface=if_CS_ModeOnCommand
      rp_NotifySleepStatus: required-interface=TI_WSS_SWCNotifySleepStatus
    behavior IB_EcuAppM
      operation invoked event OIE_ppCS_EcuAppM_EcuAppM_SetWakeupSourcesTrigByEcuAppM_SetWakeupSources: start-on-event=EcuAppM_SetWakeupSources, operation=ppCS_EcuAppM.EcuAppM_SetWakeupSources
      operation invoked event OIE_ppCS_EcuAppM_EcuAppM_InitTrigByInit: start-on-event=EcuAppM_Init, operation=ppCS_EcuAppM.Init
      timing event TEEcuAppM_MainFunction: start-on-event=EcuAppM_MainFunction, period=0.01
      port-api-options:
        enable-take-address=false, indirect-api=false, port=ppCS_EcuAppM
        enable-take-address=false, indirect-api=false, port=rpCS_EcumExt_ReleaseRUN
        enable-take-address=false, indirect-api=false, port=EcuAppM/rpCS_EcumExt_RequestRUN
        enable-take-address=false, indirect-api=false, port=rpCS_RequestPower
        enable-take-address=false, indirect-api=false, port=EcuAppM/rp_CS_Backlight_service
        enable-take-address=false, indirect-api=false, port=EcuAppM/rp_CS_NvMExt_GetNvMExtReadAllStatus
        enable-take-address=false, indirect-api=false, port=EcuAppM/rp_CS_NvMExt_SleepOperations
        enable-take-address=false, indirect-api=false, port=rp_CS_NvmExtStartReadAll
        enable-take-address=false, indirect-api=false, port=EcuAppM/rp_CS_SleepOperation
        enable-take-address=false, indirect-api=false, port=rp_CmpLibCmd_rp_CmpLibCmd_CBacklightCdd
        enable-take-address=false, indirect-api=false, port=rp_CmpLibCmd_rp_CmpLibCmd_CCDD_EcuBatteryM
        enable-take-address=false, indirect-api=false, port=rp_CmpLibCmd_rp_CmpLibCmd_CCDD_EcuPowerM
        enable-take-address=false, indirect-api=false, port=rp_CmpLibCmd_rp_CmpLibCmd_CComAbsCtrl
        enable-take-address=false, indirect-api=false, port=rp_CmpLibCmd_rp_CmpLibCmd_CComAbsMdl
        enable-take-address=false, indirect-api=false, port=rp_CmpLibCmd_rp_CmpLibCmd_CComAbsMdlSafe
        enable-take-address=false, indirect-api=false, port=rp_CmpLibCmd_rp_CmpLibCmd_CCtrl_Illumination
        enable-take-address=false, indirect-api=false, port=rp_CmpLibCmd_rp_CmpLibCmd_CCtrl_Telltale
        enable-take-address=false, indirect-api=false, port=rp_CmpLibCmd_rp_CmpLibCmd_CDcmArp
        enable-take-address=false, indirect-api=false, port=rp_CmpLibCmd_rp_CmpLibCmd_CDemArp
        enable-take-address=false, indirect-api=false, port=rp_CmpLibCmd_rp_CmpLibCmd_CDisplayCdd
        enable-take-address=false, indirect-api=false, port=rp_CmpLibCmd_rp_CmpLibCmd_CDmnMgr
        enable-take-address=false, indirect-api=false, port=rp_CmpLibCmd_rp_CmpLibCmd_CFltM
        enable-take-address=false, indirect-api=false, port=rp_CmpLibCmd_rp_CmpLibCmd_CFltMExt
        enable-take-address=false, indirect-api=false, port=rp_CmpLibCmd_rp_CmpLibCmd_CGdtCdd
        enable-take-address=false, indirect-api=false, port=rp_CmpLibCmd_rp_CmpLibCmd_CIoExp
        enable-take-address=false, indirect-api=false, port=rp_CmpLibCmd_rp_CmpLibCmd_CPmicCdd
        enable-take-address=false, indirect-api=false, port=rp_CmpLibCmd_rp_CmpLibCmd_CRTCCdd
        enable-take-address=false, indirect-api=false, port=rp_CmpLibCmd_rp_CmpLibCmd_CRstM
        enable-take-address=false, indirect-api=false, port=rp_CmpLibCmd_rp_CmpLibCmd_CSafeNvM
        enable-take-address=false, indirect-api=false, port=rp_CmpLibCmd_rp_CmpLibCmd_CSigCdd
        enable-take-address=false, indirect-api=false, port=rp_CmpLibCmd_rp_CmpLibCmd_CSndCdd
        enable-take-address=false, indirect-api=false, port=rp_CmpLibCmd_rp_CmpLibCmd_CSwcDispMonSf
        enable-take-address=false, indirect-api=false, port=rp_CmpLibCmd_rp_CmpLibCmd_CUclProxyCdd
        enable-take-address=false, indirect-api=false, port=rp_CmpLibCmd_rp_CmpLibCmd_CUpdateCdd
        enable-take-address=false, indirect-api=false, port=rp_CmpLibCmd_rp_CmpLibCmd_CView_Illumination
        enable-take-address=false, indirect-api=false, port=rp_CmpLibCmd_rp_CmpLibCmd_CView_Telltale
        enable-take-address=false, indirect-api=false, port=rp_CmpLibCmd_rp_CmpLibCmd_CWarnMsg_Core_Observer
        enable-take-address=false, indirect-api=false, port=rp_CmpLibCmd_rp_CmpLibCmd_CorTst
        enable-take-address=false, indirect-api=false, port=rp_CmpLibCmd_rp_CmpLibCmd_Ctrl_WSS
        enable-take-address=false, indirect-api=false, port=rp_CmpLibCmd_rp_CmpLibCmd_FlsTst
        enable-take-address=false, indirect-api=false, port=rp_CmpLibCmd_rp_CmpLibCmd_MeetCdd
        enable-take-address=false, indirect-api=false, port=rp_CmpLibCmd_rp_CmpLibCmd_MemAbstractMdl
        enable-take-address=false, indirect-api=false, port=rp_CmpLibCmd_rp_CmpLibCmd_RamTst
        enable-take-address=false, indirect-api=false, port=rp_CmpLibCmd_rp_CmpLibCmd_SysTst
        enable-take-address=false, indirect-api=false, port=rp_NotifySleepStatus
      runnable EcuAppM_SetWakeupSources: can-be-invoked-concurrently=true
        51 x sync call, all with timeout=0.0:
          OA_rpCS_EcumExt_ReleaseRUN_ReleaseRUN: operation=rpCS_EcumExt_ReleaseRUN.ReleaseRUN
          OA_rpCS_EcumExt_RequestRUN_RequestRUN: operation=rpCS_EcumExt_RequestRUN.RequestRUN
          OA_rpCS_RequestPower_EcuPowerM_RequestPower: operation=rpCS_RequestPower.EcuPowerM_RequestPower
          OA_rpCS_RequestPower_EcuPowerM_GetDeviceStatus: operation=rpCS_RequestPower.EcuPowerM_GetDeviceStatus
          OA_rp_CS_Backlight_service_SetBrightnessValue: operation=rp_CS_Backlight_service.SetBrightnessValue
          OA_rp_CS_Backlight_service_GetBrightnessValue: operation=rp_CS_Backlight_service.GetBrightnessValue
          OA_rp_CS_Backlight_service_GetThermalValue: operation=rp_CS_Backlight_service.GetThermalValue
          OA_rp_CS_NvMExt_GetNvMExtReadAllStatus_NvmExt_GetNvMReadAllStatus: operation=rp_CS_NvMExt_GetNvMExtReadAllStatus.NvmExt_GetNvMReadAllStatus
          OA_rp_CS_NvMExt_SleepOperations_NvMExt_ReadytoSleep: operation=rp_CS_NvMExt_SleepOperations.NvMExt_ReadytoSleep
          OA_rp_CS_NvMExt_SleepOperations_NvMExt_RequestSleep: operation=rp_CS_NvMExt_SleepOperations.NvMExt_RequestSleep
          OA_rp_CS_NvMExt_SleepOperations_NvMExt_CancelSleep: operation=rp_CS_NvMExt_SleepOperations.NvMExt_CancelSleep
          OA_rp_CS_NvmExtStartReadAll_NvMExt_ReadAll: operation=rp_CS_NvmExtStartReadAll.NvMExt_ReadAll
          OA_rp_CS_SleepOperation_CtrlWSS_ReadytoSleep: operation=rp_CS_SleepOperation.CtrlWSS_ReadytoSleep
          OA_rp_CS_SleepOperation_CtrlWSS_RequestSleep: operation=rp_CS_SleepOperation.CtrlWSS_RequestSleep
          OA_rp_CS_SleepOperation_CtrlWSS_CancelSleep: operation=rp_CS_SleepOperation.CtrlWSS_CancelSleep
          OA_rp_CmpLibCmd_rp_CmpLibCmd_CBacklightCdd_Impl_OnCommand: operation=rp_CmpLibCmd_rp_CmpLibCmd_CBacklightCdd.Impl_OnCommand
          OA_rp_CmpLibCmd_rp_CmpLibCmd_CCDD_EcuBatteryM_Impl_OnCommand: operation=rp_CmpLibCmd_rp_CmpLibCmd_CCDD_EcuBatteryM.Impl_OnCommand
          OA_rp_CmpLibCmd_rp_CmpLibCmd_CCDD_EcuPowerM_Impl_OnCommand: operation=rp_CmpLibCmd_rp_CmpLibCmd_CCDD_EcuPowerM.Impl_OnCommand
          OA_rp_CmpLibCmd_rp_CmpLibCmd_CComAbsCtrl_Impl_OnCommand: operation=rp_CmpLibCmd_rp_CmpLibCmd_CComAbsCtrl.Impl_OnCommand
          OA_rp_CmpLibCmd_rp_CmpLibCmd_CComAbsMdl_Impl_OnCommand: operation=rp_CmpLibCmd_rp_CmpLibCmd_CComAbsMdl.Impl_OnCommand
          OA_rp_CmpLibCmd_rp_CmpLibCmd_CComAbsMdlSafe_Impl_OnCommand: operation=rp_CmpLibCmd_rp_CmpLibCmd_CComAbsMdlSafe.Impl_OnCommand
          OA_rp_CmpLibCmd_rp_CmpLibCmd_CCtrl_Illumination_Impl_OnCommand: operation=rp_CmpLibCmd_rp_CmpLibCmd_CCtrl_Illumination.Impl_OnCommand
          OA_rp_CmpLibCmd_rp_CmpLibCmd_CCtrl_Telltale_Impl_OnCommand: operation=rp_CmpLibCmd_rp_CmpLibCmd_CCtrl_Telltale.Impl_OnCommand
          OA_rp_CmpLibCmd_rp_CmpLibCmd_CDcmArp_Impl_OnCommand: operation=rp_CmpLibCmd_rp_CmpLibCmd_CDcmArp.Impl_OnCommand
          OA_rp_CmpLibCmd_rp_CmpLibCmd_CDemArp_Impl_OnCommand: operation=rp_CmpLibCmd_rp_CmpLibCmd_CDemArp.Impl_OnCommand
          OA_rp_CmpLibCmd_rp_CmpLibCmd_CDisplayCdd_Impl_OnCommand: operation=rp_CmpLibCmd_rp_CmpLibCmd_CDisplayCdd.Impl_OnCommand
          OA_rp_CmpLibCmd_rp_CmpLibCmd_CDmnMgr_Impl_OnCommand: operation=rp_CmpLibCmd_rp_CmpLibCmd_CDmnMgr.Impl_OnCommand
          OA_rp_CmpLibCmd_rp_CmpLibCmd_CFltM_Impl_OnCommand: operation=rp_CmpLibCmd_rp_CmpLibCmd_CFltM.Impl_OnCommand
          OA_rp_CmpLibCmd_rp_CmpLibCmd_CFltMExt_Impl_OnCommand: operation=rp_CmpLibCmd_rp_CmpLibCmd_CFltMExt.Impl_OnCommand
          OA_rp_CmpLibCmd_rp_CmpLibCmd_CGdtCdd_Impl_OnCommand: operation=rp_CmpLibCmd_rp_CmpLibCmd_CGdtCdd.Impl_OnCommand
          OA_rp_CmpLibCmd_rp_CmpLibCmd_CIoExp_Impl_OnCommand: operation=rp_CmpLibCmd_rp_CmpLibCmd_CIoExp.Impl_OnCommand
          OA_rp_CmpLibCmd_rp_CmpLibCmd_CPmicCdd_Impl_OnCommand: operation=rp_CmpLibCmd_rp_CmpLibCmd_CPmicCdd.Impl_OnCommand
          OA_rp_CmpLibCmd_rp_CmpLibCmd_CRTCCdd_Impl_OnCommand: operation=rp_CmpLibCmd_rp_CmpLibCmd_CRTCCdd.Impl_OnCommand
          OA_rp_CmpLibCmd_rp_CmpLibCmd_CRstM_Impl_OnCommand: operation=rp_CmpLibCmd_rp_CmpLibCmd_CRstM.Impl_OnCommand
          OA_rp_CmpLibCmd_rp_CmpLibCmd_CSafeNvM_Impl_OnCommand: operation=rp_CmpLibCmd_rp_CmpLibCmd_CSafeNvM.Impl_OnCommand
          OA_rp_CmpLibCmd_rp_CmpLibCmd_CSigCdd_Impl_OnCommand: operation=rp_CmpLibCmd_rp_CmpLibCmd_CSigCdd.Impl_OnCommand
          OA_rp_CmpLibCmd_rp_CmpLibCmd_CSndCdd_Impl_OnCommand: operation=rp_CmpLibCmd_rp_CmpLibCmd_CSndCdd.Impl_OnCommand
          OA_rp_CmpLibCmd_rp_CmpLibCmd_CSwcDispMonSf_Impl_OnCommand: operation=rp_CmpLibCmd_rp_CmpLibCmd_CSwcDispMonSf.Impl_OnCommand
          OA_rp_CmpLibCmd_rp_CmpLibCmd_CUclProxyCdd_Impl_OnCommand: operation=rp_CmpLibCmd_rp_CmpLibCmd_CUclProxyCdd.Impl_OnCommand
          OA_rp_CmpLibCmd_rp_CmpLibCmd_CUpdateCdd_Impl_OnCommand: operation=rp_CmpLibCmd_rp_CmpLibCmd_CUpdateCdd.Impl_OnCommand
          OA_rp_CmpLibCmd_rp_CmpLibCmd_CView_Illumination_Impl_OnCommand: operation=rp_CmpLibCmd_rp_CmpLibCmd_CView_Illumination.Impl_OnCommand
          OA_rp_CmpLibCmd_rp_CmpLibCmd_CView_Telltale_Impl_OnCommand: operation=rp_CmpLibCmd_rp_CmpLibCmd_CView_Telltale.Impl_OnCommand
          OA_rp_CmpLibCmd_rp_CmpLibCmd_CWarnMsg_Core_Observer_Impl_OnCommand: operation=rp_CmpLibCmd_rp_CmpLibCmd_CWarnMsg_Core_Observer.Impl_OnCommand
          OA_rp_CmpLibCmd_rp_CmpLibCmd_CorTst_Impl_OnCommand: operation=rp_CmpLibCmd_rp_CmpLibCmd_CorTst.Impl_OnCommand
          OA_rp_CmpLibCmd_rp_CmpLibCmd_Ctrl_WSS_Impl_OnCommand: operation=rp_CmpLibCmd_rp_CmpLibCmd_Ctrl_WSS.Impl_OnCommand
          OA_rp_CmpLibCmd_rp_CmpLibCmd_FlsTst_Impl_OnCommand: operation=rp_CmpLibCmd_rp_CmpLibCmd_FlsTst.Impl_OnCommand
          OA_rp_CmpLibCmd_rp_CmpLibCmd_MeetCdd_Impl_OnCommand: operation=rp_CmpLibCmd_rp_CmpLibCmd_MeetCdd.Impl_OnCommand
          OA_rp_CmpLibCmd_rp_CmpLibCmd_MemAbstractMdl_Impl_OnCommand: operation=rp_CmpLibCmd_rp_CmpLibCmd_MemAbstractMdl.Impl_OnCommand
          OA_rp_CmpLibCmd_rp_CmpLibCmd_RamTst_Impl_OnCommand: operation=rp_CmpLibCmd_rp_CmpLibCmd_RamTst.Impl_OnCommand
          OA_rp_CmpLibCmd_rp_CmpLibCmd_SysTst_Impl_OnCommand: operation=rp_CmpLibCmd_rp_CmpLibCmd_SysTst.Impl_OnCommand
          OA_rp_NotifySleepStatus_CtrlWSS_NotifyNetworkSleep: operation=rp_NotifySleepStatus.CtrlWSS_NotifyNetworkSleep
      runnable EcuAppM_Init: can-be-invoked-concurrently=true
        51 x sync call, all with timeout=0.0:
          OA_rpCS_EcumExt_ReleaseRUN_ReleaseRUN: operation=rpCS_EcumExt_ReleaseRUN.ReleaseRUN
          OA_rpCS_EcumExt_RequestRUN_RequestRUN: operation=rpCS_EcumExt_RequestRUN.RequestRUN
          OA_rpCS_RequestPower_EcuPowerM_RequestPower: operation=rpCS_RequestPower.EcuPowerM_RequestPower
          OA_rpCS_RequestPower_EcuPowerM_GetDeviceStatus: operation=rpCS_RequestPower.EcuPowerM_GetDeviceStatus
          OA_rp_CS_Backlight_service_SetBrightnessValue: operation=rp_CS_Backlight_service.SetBrightnessValue
          OA_rp_CS_Backlight_service_GetBrightnessValue: operation=rp_CS_Backlight_service.GetBrightnessValue
          OA_rp_CS_Backlight_service_GetThermalValue: operation=rp_CS_Backlight_service.GetThermalValue
          OA_rp_CS_NvMExt_GetNvMExtReadAllStatus_NvmExt_GetNvMReadAllStatus: operation=rp_CS_NvMExt_GetNvMExtReadAllStatus.NvmExt_GetNvMReadAllStatus
          OA_rp_CS_NvMExt_SleepOperations_NvMExt_ReadytoSleep: operation=rp_CS_NvMExt_SleepOperations.NvMExt_ReadytoSleep
          OA_rp_CS_NvMExt_SleepOperations_NvMExt_RequestSleep: operation=rp_CS_NvMExt_SleepOperations.NvMExt_RequestSleep
          OA_rp_CS_NvMExt_SleepOperations_NvMExt_CancelSleep: operation=rp_CS_NvMExt_SleepOperations.NvMExt_CancelSleep
          OA_rp_CS_NvmExtStartReadAll_NvMExt_ReadAll: operation=rp_CS_NvmExtStartReadAll.NvMExt_ReadAll
          OA_rp_CS_SleepOperation_CtrlWSS_ReadytoSleep: operation=rp_CS_SleepOperation.CtrlWSS_ReadytoSleep
          OA_rp_CS_SleepOperation_CtrlWSS_RequestSleep: operation=rp_CS_SleepOperation.CtrlWSS_RequestSleep
          OA_rp_CS_SleepOperation_CtrlWSS_CancelSleep: operation=rp_CS_SleepOperation.CtrlWSS_CancelSleep
          OA_rp_CmpLibCmd_rp_CmpLibCmd_CBacklightCdd_Impl_OnCommand: operation=rp_CmpLibCmd_rp_CmpLibCmd_CBacklightCdd.Impl_OnCommand
          OA_rp_CmpLibCmd_rp_CmpLibCmd_CCDD_EcuBatteryM_Impl_OnCommand: operation=rp_CmpLibCmd_rp_CmpLibCmd_CCDD_EcuBatteryM.Impl_OnCommand
          OA_rp_CmpLibCmd_rp_CmpLibCmd_CCDD_EcuPowerM_Impl_OnCommand: operation=rp_CmpLibCmd_rp_CmpLibCmd_CCDD_EcuPowerM.Impl_OnCommand
          OA_rp_CmpLibCmd_rp_CmpLibCmd_CComAbsCtrl_Impl_OnCommand: operation=rp_CmpLibCmd_rp_CmpLibCmd_CComAbsCtrl.Impl_OnCommand
          OA_rp_CmpLibCmd_rp_CmpLibCmd_CComAbsMdl_Impl_OnCommand: operation=rp_CmpLibCmd_rp_CmpLibCmd_CComAbsMdl.Impl_OnCommand
          OA_rp_CmpLibCmd_rp_CmpLibCmd_CComAbsMdlSafe_Impl_OnCommand: operation=rp_CmpLibCmd_rp_CmpLibCmd_CComAbsMdlSafe.Impl_OnCommand
          OA_rp_CmpLibCmd_rp_CmpLibCmd_CCtrl_Illumination_Impl_OnCommand: operation=rp_CmpLibCmd_rp_CmpLibCmd_CCtrl_Illumination.Impl_OnCommand
          OA_rp_CmpLibCmd_rp_CmpLibCmd_CCtrl_Telltale_Impl_OnCommand: operation=rp_CmpLibCmd_rp_CmpLibCmd_CCtrl_Telltale.Impl_OnCommand
          OA_rp_CmpLibCmd_rp_CmpLibCmd_CDcmArp_Impl_OnCommand: operation=rp_CmpLibCmd_rp_CmpLibCmd_CDcmArp.Impl_OnCommand
          OA_rp_CmpLibCmd_rp_CmpLibCmd_CDemArp_Impl_OnCommand: operation=rp_CmpLibCmd_rp_CmpLibCmd_CDemArp.Impl_OnCommand
          OA_rp_CmpLibCmd_rp_CmpLibCmd_CDisplayCdd_Impl_OnCommand: operation=rp_CmpLibCmd_rp_CmpLibCmd_CDisplayCdd.Impl_OnCommand
          OA_rp_CmpLibCmd_rp_CmpLibCmd_CDmnMgr_Impl_OnCommand: operation=rp_CmpLibCmd_rp_CmpLibCmd_CDmnMgr.Impl_OnCommand
          OA_rp_CmpLibCmd_rp_CmpLibCmd_CFltM_Impl_OnCommand: operation=rp_CmpLibCmd_rp_CmpLibCmd_CFltM.Impl_OnCommand
          OA_rp_CmpLibCmd_rp_CmpLibCmd_CFltMExt_Impl_OnCommand: operation=rp_CmpLibCmd_rp_CmpLibCmd_CFltMExt.Impl_OnCommand
          OA_rp_CmpLibCmd_rp_CmpLibCmd_CGdtCdd_Impl_OnCommand: operation=rp_CmpLibCmd_rp_CmpLibCmd_CGdtCdd.Impl_OnCommand
          OA_rp_CmpLibCmd_rp_CmpLibCmd_CIoExp_Impl_OnCommand: operation=rp_CmpLibCmd_rp_CmpLibCmd_CIoExp.Impl_OnCommand
          OA_rp_CmpLibCmd_rp_CmpLibCmd_CPmicCdd_Impl_OnCommand: operation=rp_CmpLibCmd_rp_CmpLibCmd_CPmicCdd.Impl_OnCommand
          OA_rp_CmpLibCmd_rp_CmpLibCmd_CRTCCdd_Impl_OnCommand: operation=rp_CmpLibCmd_rp_CmpLibCmd_CRTCCdd.Impl_OnCommand
          OA_rp_CmpLibCmd_rp_CmpLibCmd_CRstM_Impl_OnCommand: operation=rp_CmpLibCmd_rp_CmpLibCmd_CRstM.Impl_OnCommand
          OA_rp_CmpLibCmd_rp_CmpLibCmd_CSafeNvM_Impl_OnCommand: operation=rp_CmpLibCmd_rp_CmpLibCmd_CSafeNvM.Impl_OnCommand
          OA_rp_CmpLibCmd_rp_CmpLibCmd_CSigCdd_Impl_OnCommand: operation=rp_CmpLibCmd_rp_CmpLibCmd_CSigCdd.Impl_OnCommand
          OA_rp_CmpLibCmd_rp_CmpLibCmd_CSndCdd_Impl_OnCommand: operation=rp_CmpLibCmd_rp_CmpLibCmd_CSndCdd.Impl_OnCommand
          OA_rp_CmpLibCmd_rp_CmpLibCmd_CSwcDispMonSf_Impl_OnCommand: operation=rp_CmpLibCmd_rp_CmpLibCmd_CSwcDispMonSf.Impl_OnCommand
          OA_rp_CmpLibCmd_rp_CmpLibCmd_CUclProxyCdd_Impl_OnCommand: operation=rp_CmpLibCmd_rp_CmpLibCmd_CUclProxyCdd.Impl_OnCommand
          OA_rp_CmpLibCmd_rp_CmpLibCmd_CUpdateCdd_Impl_OnCommand: operation=rp_CmpLibCmd_rp_CmpLibCmd_CUpdateCdd.Impl_OnCommand
          OA_rp_CmpLibCmd_rp_CmpLibCmd_CView_Illumination_Impl_OnCommand: operation=rp_CmpLibCmd_rp_CmpLibCmd_CView_Illumination.Impl_OnCommand
          OA_rp_CmpLibCmd_rp_CmpLibCmd_CView_Telltale_Impl_OnCommand: operation=rp_CmpLibCmd_rp_CmpLibCmd_CView_Telltale.Impl_OnCommand
          OA_rp_CmpLibCmd_rp_CmpLibCmd_CWarnMsg_Core_Observer_Impl_OnCommand: operation=rp_CmpLibCmd_rp_CmpLibCmd_CWarnMsg_Core_Observer.Impl_OnCommand
          OA_rp_CmpLibCmd_rp_CmpLibCmd_CorTst_Impl_OnCommand: operation=rp_CmpLibCmd_rp_CmpLibCmd_CorTst.Impl_OnCommand
          OA_rp_CmpLibCmd_rp_CmpLibCmd_Ctrl_WSS_Impl_OnCommand: operation=rp_CmpLibCmd_rp_CmpLibCmd_Ctrl_WSS.Impl_OnCommand
          OA_rp_CmpLibCmd_rp_CmpLibCmd_FlsTst_Impl_OnCommand: operation=rp_CmpLibCmd_rp_CmpLibCmd_FlsTst.Impl_OnCommand
          OA_rp_CmpLibCmd_rp_CmpLibCmd_MeetCdd_Impl_OnCommand: operation=rp_CmpLibCmd_rp_CmpLibCmd_MeetCdd.Impl_OnCommand
          OA_rp_CmpLibCmd_rp_CmpLibCmd_MemAbstractMdl_Impl_OnCommand: operation=rp_CmpLibCmd_rp_CmpLibCmd_MemAbstractMdl.Impl_OnCommand
          OA_rp_CmpLibCmd_rp_CmpLibCmd_RamTst_Impl_OnCommand: operation=rp_CmpLibCmd_rp_CmpLibCmd_RamTst.Impl_OnCommand
          OA_rp_CmpLibCmd_rp_CmpLibCmd_SysTst_Impl_OnCommand: operation=rp_CmpLibCmd_rp_CmpLibCmd_SysTst.Impl_OnCommand
          OA_rp_NotifySleepStatus_CtrlWSS_NotifyNetworkSleep: operation=rp_NotifySleepStatus.CtrlWSS_NotifyNetworkSleep
      runnable EcuAppM_MainFunction: can-be-invoked-concurrently=true
        51 x sync call, all with timeout=0.0:
          OA_rpCS_EcumExt_ReleaseRUN_ReleaseRUN: operation=rpCS_EcumExt_ReleaseRUN.ReleaseRUN
          OA_rpCS_EcumExt_RequestRUN_RequestRUN: operation=rpCS_EcumExt_RequestRUN.RequestRUN
          OA_rpCS_RequestPower_EcuPowerM_RequestPower: operation=rpCS_RequestPower.EcuPowerM_RequestPower
          OA_rpCS_RequestPower_EcuPowerM_GetDeviceStatus: operation=rpCS_RequestPower.EcuPowerM_GetDeviceStatus
          OA_rp_CS_Backlight_service_SetBrightnessValue: operation=rp_CS_Backlight_service.SetBrightnessValue
          OA_rp_CS_Backlight_service_GetBrightnessValue: operation=rp_CS_Backlight_service.GetBrightnessValue
          OA_rp_CS_Backlight_service_GetThermalValue: operation=rp_CS_Backlight_service.GetThermalValue
          OA_rp_CS_NvMExt_GetNvMExtReadAllStatus_NvmExt_GetNvMReadAllStatus: operation=rp_CS_NvMExt_GetNvMExtReadAllStatus.NvmExt_GetNvMReadAllStatus
          OA_rp_CS_NvMExt_SleepOperations_NvMExt_ReadytoSleep: operation=rp_CS_NvMExt_SleepOperations.NvMExt_ReadytoSleep
          OA_rp_CS_NvMExt_SleepOperations_NvMExt_RequestSleep: operation=rp_CS_NvMExt_SleepOperations.NvMExt_RequestSleep
          OA_rp_CS_NvMExt_SleepOperations_NvMExt_CancelSleep: operation=rp_CS_NvMExt_SleepOperations.NvMExt_CancelSleep
          OA_rp_CS_NvmExtStartReadAll_NvMExt_ReadAll: operation=rp_CS_NvmExtStartReadAll.NvMExt_ReadAll
          OA_rp_CS_SleepOperation_CtrlWSS_ReadytoSleep: operation=rp_CS_SleepOperation.CtrlWSS_ReadytoSleep
          OA_rp_CS_SleepOperation_CtrlWSS_RequestSleep: operation=rp_CS_SleepOperation.CtrlWSS_RequestSleep
          OA_rp_CS_SleepOperation_CtrlWSS_CancelSleep: operation=rp_CS_SleepOperation.CtrlWSS_CancelSleep
          OA_rp_CmpLibCmd_rp_CmpLibCmd_CBacklightCdd_Impl_OnCommand: operation=rp_CmpLibCmd_rp_CmpLibCmd_CBacklightCdd.Impl_OnCommand
          OA_rp_CmpLibCmd_rp_CmpLibCmd_CCDD_EcuBatteryM_Impl_OnCommand: operation=rp_CmpLibCmd_rp_CmpLibCmd_CCDD_EcuBatteryM.Impl_OnCommand
          OA_rp_CmpLibCmd_rp_CmpLibCmd_CCDD_EcuPowerM_Impl_OnCommand: operation=rp_CmpLibCmd_rp_CmpLibCmd_CCDD_EcuPowerM.Impl_OnCommand
          OA_rp_CmpLibCmd_rp_CmpLibCmd_CComAbsCtrl_Impl_OnCommand: operation=rp_CmpLibCmd_rp_CmpLibCmd_CComAbsCtrl.Impl_OnCommand
          OA_rp_CmpLibCmd_rp_CmpLibCmd_CComAbsMdl_Impl_OnCommand: operation=rp_CmpLibCmd_rp_CmpLibCmd_CComAbsMdl.Impl_OnCommand
          OA_rp_CmpLibCmd_rp_CmpLibCmd_CComAbsMdlSafe_Impl_OnCommand: operation=rp_CmpLibCmd_rp_CmpLibCmd_CComAbsMdlSafe.Impl_OnCommand
          OA_rp_CmpLibCmd_rp_CmpLibCmd_CCtrl_Illumination_Impl_OnCommand: operation=rp_CmpLibCmd_rp_CmpLibCmd_CCtrl_Illumination.Impl_OnCommand
          OA_rp_CmpLibCmd_rp_CmpLibCmd_CCtrl_Telltale_Impl_OnCommand: operation=rp_CmpLibCmd_rp_CmpLibCmd_CCtrl_Telltale.Impl_OnCommand
          OA_rp_CmpLibCmd_rp_CmpLibCmd_CDcmArp_Impl_OnCommand: operation=rp_CmpLibCmd_rp_CmpLibCmd_CDcmArp.Impl_OnCommand
          OA_rp_CmpLibCmd_rp_CmpLibCmd_CDemArp_Impl_OnCommand: operation=rp_CmpLibCmd_rp_CmpLibCmd_CDemArp.Impl_OnCommand
          OA_rp_CmpLibCmd_rp_CmpLibCmd_CDisplayCdd_Impl_OnCommand: operation=rp_CmpLibCmd_rp_CmpLibCmd_CDisplayCdd.Impl_OnCommand
          OA_rp_CmpLibCmd_rp_CmpLibCmd_CDmnMgr_Impl_OnCommand: operation=rp_CmpLibCmd_rp_CmpLibCmd_CDmnMgr.Impl_OnCommand
          OA_rp_CmpLibCmd_rp_CmpLibCmd_CFltM_Impl_OnCommand: operation=rp_CmpLibCmd_rp_CmpLibCmd_CFltM.Impl_OnCommand
          OA_rp_CmpLibCmd_rp_CmpLibCmd_CFltMExt_Impl_OnCommand: operation=rp_CmpLibCmd_rp_CmpLibCmd_CFltMExt.Impl_OnCommand
          OA_rp_CmpLibCmd_rp_CmpLibCmd_CGdtCdd_Impl_OnCommand: operation=rp_CmpLibCmd_rp_CmpLibCmd_CGdtCdd.Impl_OnCommand
          OA_rp_CmpLibCmd_rp_CmpLibCmd_CIoExp_Impl_OnCommand: operation=rp_CmpLibCmd_rp_CmpLibCmd_CIoExp.Impl_OnCommand
          OA_rp_CmpLibCmd_rp_CmpLibCmd_CPmicCdd_Impl_OnCommand: operation=rp_CmpLibCmd_rp_CmpLibCmd_CPmicCdd.Impl_OnCommand
          OA_rp_CmpLibCmd_rp_CmpLibCmd_CRTCCdd_Impl_OnCommand: operation=rp_CmpLibCmd_rp_CmpLibCmd_CRTCCdd.Impl_OnCommand
          OA_rp_CmpLibCmd_rp_CmpLibCmd_CRstM_Impl_OnCommand: operation=rp_CmpLibCmd_rp_CmpLibCmd_CRstM.Impl_OnCommand
          OA_rp_CmpLibCmd_rp_CmpLibCmd_CSafeNvM_Impl_OnCommand: operation=rp_CmpLibCmd_rp_CmpLibCmd_CSafeNvM.Impl_OnCommand
          OA_rp_CmpLibCmd_rp_CmpLibCmd_CSigCdd_Impl_OnCommand: operation=rp_CmpLibCmd_rp_CmpLibCmd_CSigCdd.Impl_OnCommand
          OA_rp_CmpLibCmd_rp_CmpLibCmd_CSndCdd_Impl_OnCommand: operation=rp_CmpLibCmd_rp_CmpLibCmd_CSndCdd.Impl_OnCommand
          OA_rp_CmpLibCmd_rp_CmpLibCmd_CSwcDispMonSf_Impl_OnCommand: operation=rp_CmpLibCmd_rp_CmpLibCmd_CSwcDispMonSf.Impl_OnCommand
          OA_rp_CmpLibCmd_rp_CmpLibCmd_CUclProxyCdd_Impl_OnCommand: operation=rp_CmpLibCmd_rp_CmpLibCmd_CUclProxyCdd.Impl_OnCommand
          OA_rp_CmpLibCmd_rp_CmpLibCmd_CUpdateCdd_Impl_OnCommand: operation=rp_CmpLibCmd_rp_CmpLibCmd_CUpdateCdd.Impl_OnCommand
          OA_rp_CmpLibCmd_rp_CmpLibCmd_CView_Illumination_Impl_OnCommand: operation=rp_CmpLibCmd_rp_CmpLibCmd_CView_Illumination.Impl_OnCommand
          OA_rp_CmpLibCmd_rp_CmpLibCmd_CView_Telltale_Impl_OnCommand: operation=rp_CmpLibCmd_rp_CmpLibCmd_CView_Telltale.Impl_OnCommand
          OA_rp_CmpLibCmd_rp_CmpLibCmd_CWarnMsg_Core_Observer_Impl_OnCommand: operation=rp_CmpLibCmd_rp_CmpLibCmd_CWarnMsg_Core_Observer.Impl_OnCommand
          OA_rp_CmpLibCmd_rp_CmpLibCmd_CorTst_Impl_OnCommand: operation=rp_CmpLibCmd_rp_CmpLibCmd_CorTst.Impl_OnCommand
          OA_rp_CmpLibCmd_rp_CmpLibCmd_Ctrl_WSS_Impl_OnCommand: operation=rp_CmpLibCmd_rp_CmpLibCmd_Ctrl_WSS.Impl_OnCommand
          OA_rp_CmpLibCmd_rp_CmpLibCmd_FlsTst_Impl_OnCommand: operation=rp_CmpLibCmd_rp_CmpLibCmd_FlsTst.Impl_OnCommand
          OA_rp_CmpLibCmd_rp_CmpLibCmd_MeetCdd_Impl_OnCommand: operation=rp_CmpLibCmd_rp_CmpLibCmd_MeetCdd.Impl_OnCommand
          OA_rp_CmpLibCmd_rp_CmpLibCmd_MemAbstractMdl_Impl_OnCommand: operation=rp_CmpLibCmd_rp_CmpLibCmd_MemAbstractMdl.Impl_OnCommand
          OA_rp_CmpLibCmd_rp_CmpLibCmd_RamTst_Impl_OnCommand: operation=rp_CmpLibCmd_rp_CmpLibCmd_RamTst.Impl_OnCommand
          OA_rp_CmpLibCmd_rp_CmpLibCmd_SysTst_Impl_OnCommand: operation=rp_CmpLibCmd_rp_CmpLibCmd_SysTst.Impl_OnCommand
          OA_rp_NotifySleepStatus_CtrlWSS_NotifyNetworkSleep: operation=rp_NotifySleepStatus.CtrlWSS_NotifyNetworkSleep
  swc implementation IMPL_EcuAppM: programming-language=C, behavior=IB_EcuAppM
    code-descriptors:
      code CodeDescriptor
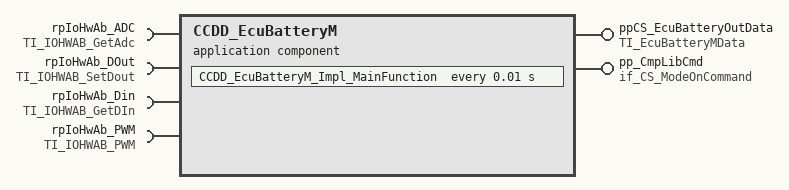
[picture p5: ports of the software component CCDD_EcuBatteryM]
  application sw component type CCDD_EcuBatteryM
    provide port ppCS_EcuBatteryOutData: provided-interface=TI_EcuBatteryMData
      provided-com-specs:
        operation=EcuBatteryM_GetChannelStatus, queue-length=1
        operation=EcuBatteryM_GetDIOStatus, queue-length=1
    provide port pp_CmpLibCmd: server-com-spec{operation=Impl_OnCommand, queue-length=1}, provided-interface=if_CS_ModeOnCommand
    4 x require port:
      rpIoHwAb_ADC: required-interface=TI_IOHWAB_GetAdc
      rpIoHwAb_DOut: required-interface=TI_IOHWAB_SetDout
      rpIoHwAb_Din: required-interface=TI_IOHWAB_GetDIn
      rpIoHwAb_PWM: required-interface=TI_IOHWAB_PWM
    behavior IB_CCDD_EcuBatteryM
      timing event TECCDD_EcuBatteryM_Impl_MainFunction: start-on-event=CCDD_EcuBatteryM_Impl_MainFunction, period=0.01
      operation invoked event OIE_ppCS_EcuBatteryOutData_EcuBatteryM_GetChannelStatusTrigByEcuBatteryM_GetChannelStatus: start-on-event=EcuBatteryM_GetChannelStatus, operation=ppCS_EcuBatteryOutData.EcuBatteryM_GetChannelStatus
      operation invoked event OIE_ppCS_EcuBatteryOutData_EcuBatteryM_GetDIOStatusTrigByEcuBatteryM_GetDIOStatus: start-on-event=EcuBatteryM_GetDIOStatus, operation=ppCS_EcuBatteryOutData.EcuBatteryM_GetDIOStatus
      operation invoked event OIE_pp_CmpLibCmd_CCDD_EcuBatteryM_Impl_OnCommandTrigByImpl_OnCommand: start-on-event=CCDD_EcuBatteryM_Impl_OnCommand, operation=pp_CmpLibCmd.Impl_OnCommand
      port-api-options:
        enable-take-address=false, indirect-api=false, port=ppCS_EcuBatteryOutData
        enable-take-address=false, indirect-api=false, port=CCDD_EcuBatteryM/pp_CmpLibCmd
        enable-take-address=false, indirect-api=false, port=CCDD_EcuBatteryM/rpIoHwAb_ADC
        enable-take-address=false, indirect-api=false, port=CCDD_EcuBatteryM/rpIoHwAb_DOut
        enable-take-address=false, indirect-api=false, port=CCDD_EcuBatteryM/rpIoHwAb_Din
        enable-take-address=false, indirect-api=false, port=CCDD_EcuBatteryM/rpIoHwAb_PWM
      4 x runnable, all with can-be-invoked-concurrently=true:
        CCDD_EcuBatteryM_Impl_MainFunction
          12 x sync call, all with timeout=0.0:
            OA_rpIoHwAb_ADC_GetAsyncRawAdc: operation=rpIoHwAb_ADC.GetAsyncRawAdc
            OA_rpIoHwAb_ADC_GetSyncRawAdc: operation=rpIoHwAb_ADC.GetSyncRawAdc
            OA_rpIoHwAb_ADC_GetProcessedAdc: operation=rpIoHwAb_ADC.GetProcessedAdc
            OA_rpIoHwAb_DOut_SetOutputGroup: operation=rpIoHwAb_DOut.SetOutputGroup
            OA_rpIoHwAb_DOut_SetOutputPin: operation=rpIoHwAb_DOut.SetOutputPin
            OA_rpIoHwAb_Din_GetAsyncRawInput: operation=rpIoHwAb_Din.GetAsyncRawInput
            OA_rpIoHwAb_Din_GetProcessedInput: operation=rpIoHwAb_Din.GetProcessedInput
            OA_rpIoHwAb_Din_GetSyncRawInput: operation=rpIoHwAb_Din.GetSyncRawInput
            OA_rpIoHwAb_Din_GetInputGroup: operation=rpIoHwAb_Din.GetInputGroup
            OA_rpIoHwAb_PWM_PwmSetDuty: operation=rpIoHwAb_PWM.PwmSetDuty
            OA_rpIoHwAb_PWM_PwmSetDutyAndPeriod: operation=rpIoHwAb_PWM.PwmSetDutyAndPeriod
            OA_rpIoHwAb_PWM_PwmSetIdeal: operation=rpIoHwAb_PWM.PwmSetIdeal
        EcuBatteryM_GetChannelStatus
        EcuBatteryM_GetDIOStatus
        CCDD_EcuBatteryM_Impl_OnCommand
  swc implementation IMPL_CCDD_EcuBatteryM: programming-language=C, behavior=IB_CCDD_EcuBatteryM
    code-descriptors:
      code CodeDescriptor
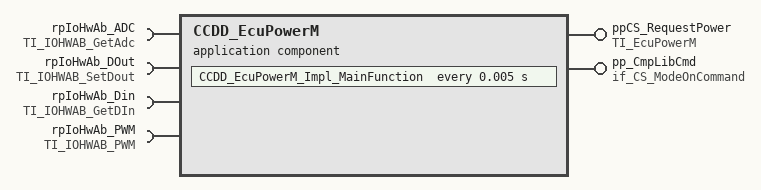
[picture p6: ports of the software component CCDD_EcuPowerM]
  application sw component type CCDD_EcuPowerM
    provide port ppCS_RequestPower: provided-interface=TI_EcuPowerM
      provided-com-specs:
        operation=EcuPowerM_GetDeviceStatus, queue-length=1
        operation=EcuPowerM_RequestPower, queue-length=1
    provide port pp_CmpLibCmd: server-com-spec{operation=Impl_OnCommand, queue-length=1}, provided-interface=if_CS_ModeOnCommand
    4 x require port:
      rpIoHwAb_ADC: required-interface=TI_IOHWAB_GetAdc
      rpIoHwAb_DOut: required-interface=TI_IOHWAB_SetDout
      rpIoHwAb_Din: required-interface=TI_IOHWAB_GetDIn
      rpIoHwAb_PWM: required-interface=TI_IOHWAB_PWM
    behavior IB_CCDD_EcuPowerM
      timing event TECCDD_EcuPowerM_Impl_MainFunction: start-on-event=CCDD_EcuPowerM_Impl_MainFunction, period=0.005
      operation invoked event OIE_ppCS_RequestPower_EcuPowerM_GetDeviceStatusTrigByEcuPowerM_GetDeviceStatus: start-on-event=EcuPowerM_GetDeviceStatus, operation=ppCS_RequestPower.EcuPowerM_GetDeviceStatus
      operation invoked event OIE_ppCS_RequestPower_EcuPowerM_RequestPowerTrigByEcuPowerM_RequestPower: start-on-event=EcuPowerM_RequestPower, operation=ppCS_RequestPower.EcuPowerM_RequestPower
      operation invoked event OIE_pp_CmpLibCmd_CCDD_EcuPowerM_Impl_OnCommandTrigByImpl_OnCommand: start-on-event=CCDD_EcuPowerM_Impl_OnCommand, operation=pp_CmpLibCmd.Impl_OnCommand
      port-api-options:
        enable-take-address=false, indirect-api=false, port=ppCS_RequestPower
        enable-take-address=false, indirect-api=false, port=CCDD_EcuPowerM/pp_CmpLibCmd
        enable-take-address=false, indirect-api=false, port=CCDD_EcuPowerM/rpIoHwAb_ADC
        enable-take-address=false, indirect-api=false, port=CCDD_EcuPowerM/rpIoHwAb_DOut
        enable-take-address=false, indirect-api=false, port=CCDD_EcuPowerM/rpIoHwAb_Din
        enable-take-address=false, indirect-api=false, port=CCDD_EcuPowerM/rpIoHwAb_PWM
      4 x runnable, all with can-be-invoked-concurrently=true:
        CCDD_EcuPowerM_Impl_MainFunction
          12 x sync call, all with timeout=0.0:
            OA_rpIoHwAb_ADC_GetAsyncRawAdc: operation=rpIoHwAb_ADC.GetAsyncRawAdc
            OA_rpIoHwAb_ADC_GetSyncRawAdc: operation=rpIoHwAb_ADC.GetSyncRawAdc
            OA_rpIoHwAb_ADC_GetProcessedAdc: operation=rpIoHwAb_ADC.GetProcessedAdc
            OA_rpIoHwAb_DOut_SetOutputGroup: operation=rpIoHwAb_DOut.SetOutputGroup
            OA_rpIoHwAb_DOut_SetOutputPin: operation=rpIoHwAb_DOut.SetOutputPin
            OA_rpIoHwAb_Din_GetAsyncRawInput: operation=rpIoHwAb_Din.GetAsyncRawInput
            OA_rpIoHwAb_Din_GetProcessedInput: operation=rpIoHwAb_Din.GetProcessedInput
            OA_rpIoHwAb_Din_GetSyncRawInput: operation=rpIoHwAb_Din.GetSyncRawInput
            OA_rpIoHwAb_Din_GetInputGroup: operation=rpIoHwAb_Din.GetInputGroup
            OA_rpIoHwAb_PWM_PwmSetDuty: operation=rpIoHwAb_PWM.PwmSetDuty
            OA_rpIoHwAb_PWM_PwmSetDutyAndPeriod: operation=rpIoHwAb_PWM.PwmSetDutyAndPeriod
            OA_rpIoHwAb_PWM_PwmSetIdeal: operation=rpIoHwAb_PWM.PwmSetIdeal
        EcuPowerM_GetDeviceStatus
          12 x sync call, all with timeout=0.0:
            OA_rpIoHwAb_ADC_GetAsyncRawAdc: operation=rpIoHwAb_ADC.GetAsyncRawAdc
            OA_rpIoHwAb_ADC_GetSyncRawAdc: operation=rpIoHwAb_ADC.GetSyncRawAdc
            OA_rpIoHwAb_ADC_GetProcessedAdc: operation=rpIoHwAb_ADC.GetProcessedAdc
            OA_rpIoHwAb_DOut_SetOutputGroup: operation=rpIoHwAb_DOut.SetOutputGroup
            OA_rpIoHwAb_DOut_SetOutputPin: operation=rpIoHwAb_DOut.SetOutputPin
            OA_rpIoHwAb_Din_GetAsyncRawInput: operation=rpIoHwAb_Din.GetAsyncRawInput
            OA_rpIoHwAb_Din_GetProcessedInput: operation=rpIoHwAb_Din.GetProcessedInput
            OA_rpIoHwAb_Din_GetSyncRawInput: operation=rpIoHwAb_Din.GetSyncRawInput
            OA_rpIoHwAb_Din_GetInputGroup: operation=rpIoHwAb_Din.GetInputGroup
            OA_rpIoHwAb_PWM_PwmSetDuty: operation=rpIoHwAb_PWM.PwmSetDuty
            OA_rpIoHwAb_PWM_PwmSetDutyAndPeriod: operation=rpIoHwAb_PWM.PwmSetDutyAndPeriod
            OA_rpIoHwAb_PWM_PwmSetIdeal: operation=rpIoHwAb_PWM.PwmSetIdeal
        EcuPowerM_RequestPower
          12 x sync call, all with timeout=0.0:
            OA_rpIoHwAb_ADC_GetAsyncRawAdc: operation=rpIoHwAb_ADC.GetAsyncRawAdc
            OA_rpIoHwAb_ADC_GetSyncRawAdc: operation=rpIoHwAb_ADC.GetSyncRawAdc
            OA_rpIoHwAb_ADC_GetProcessedAdc: operation=rpIoHwAb_ADC.GetProcessedAdc
            OA_rpIoHwAb_DOut_SetOutputGroup: operation=rpIoHwAb_DOut.SetOutputGroup
            OA_rpIoHwAb_DOut_SetOutputPin: operation=rpIoHwAb_DOut.SetOutputPin
            OA_rpIoHwAb_Din_GetAsyncRawInput: operation=rpIoHwAb_Din.GetAsyncRawInput
            OA_rpIoHwAb_Din_GetProcessedInput: operation=rpIoHwAb_Din.GetProcessedInput
            OA_rpIoHwAb_Din_GetSyncRawInput: operation=rpIoHwAb_Din.GetSyncRawInput
            OA_rpIoHwAb_Din_GetInputGroup: operation=rpIoHwAb_Din.GetInputGroup
            OA_rpIoHwAb_PWM_PwmSetDuty: operation=rpIoHwAb_PWM.PwmSetDuty
            OA_rpIoHwAb_PWM_PwmSetDutyAndPeriod: operation=rpIoHwAb_PWM.PwmSetDutyAndPeriod
            OA_rpIoHwAb_PWM_PwmSetIdeal: operation=rpIoHwAb_PWM.PwmSetIdeal
        CCDD_EcuPowerM_Impl_OnCommand
  swc implementation IMPL_CCDD_EcuPowerM: programming-language=C, behavior=IB_CCDD_EcuPowerM
    code-descriptors:
      code CodeDescriptor
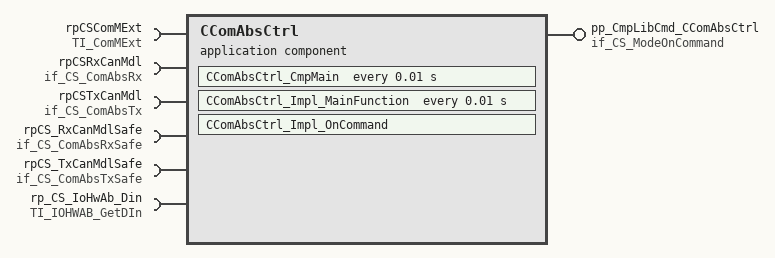
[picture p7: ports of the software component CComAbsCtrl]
  application sw component type CComAbsCtrl
    provide port pp_CmpLibCmd_CComAbsCtrl: server-com-spec{operation=Impl_OnCommand, queue-length=1}, provided-interface=if_CS_ModeOnCommand
    6 x require port:
      rpCSComMExt: required-interface=TI_ComMExt
      rpCSRxCanMdl: required-interface=if_CS_ComAbsRx
      rpCSTxCanMdl: required-interface=if_CS_ComAbsTx
      rpCS_RxCanMdlSafe: required-interface=if_CS_ComAbsRxSafe
      rpCS_TxCanMdlSafe: required-interface=if_CS_ComAbsTxSafe
      rp_CS_IoHwAb_Din: required-interface=TI_IOHWAB_GetDIn
    behavior IB_CComAbsCtrl
      timing event TECComAbsCtrl_CmpMain: start-on-event=CComAbsCtrl_CmpMain, period=0.01
      timing event TECComAbsCtrl_Impl_MainFunction: start-on-event=CComAbsCtrl_Impl_MainFunction, period=0.01
      operation invoked event OIE_pp_CmpLibCmd_CComAbsCtrl_CComAbsCtrl_Impl_OnCommandTrigByImpl_OnCommand: start-on-event=CComAbsCtrl_Impl_OnCommand, operation=pp_CmpLibCmd_CComAbsCtrl.Impl_OnCommand
      port-api-options:
        enable-take-address=false, indirect-api=false, port=pp_CmpLibCmd_CComAbsCtrl
        enable-take-address=false, indirect-api=false, port=rpCSComMExt
        enable-take-address=false, indirect-api=false, port=rpCSRxCanMdl
        enable-take-address=false, indirect-api=false, port=rpCSTxCanMdl
        enable-take-address=false, indirect-api=false, port=rpCS_RxCanMdlSafe
        enable-take-address=false, indirect-api=false, port=rpCS_TxCanMdlSafe
        enable-take-address=false, indirect-api=false, port=rp_CS_IoHwAb_Din
      runnable CComAbsCtrl_CmpMain: can-be-invoked-concurrently=true
      runnable CComAbsCtrl_Impl_MainFunction: can-be-invoked-concurrently=true
        45 x sync call, all with timeout=0.0:
          OA_rpCSComMExt_Get_MCAN_ERR_PIN_Status: operation=rpCSComMExt.Get_MCAN_ERR_PIN_Status
          OA_rpCSComMExt_Init: operation=rpCSComMExt.Init
          OA_rpCSComMExt_GetBusOffStatus: operation=rpCSComMExt.GetBusOffStatus
          OA_rpCSComMExt_CAN_RequestCommunication: operation=rpCSComMExt.CAN_RequestCommunication
          OA_rpCSComMExt_CAN_GetCurrentComMode: operation=rpCSComMExt.CAN_GetCurrentComMode
          OA_rpCSComMExt_CAN_ReleaseCommunication: operation=rpCSComMExt.CAN_ReleaseCommunication
          OA_rpCSComMExt_CAN_DeActivateSilentCommunication: operation=rpCSComMExt.CAN_DeActivateSilentCommunication
          OA_rpCSComMExt_CAN_CommControlSetDone: operation=rpCSComMExt.CAN_CommControlSetDone
          OA_rpCSComMExt_CAN_CommControlDeActivateTx: operation=rpCSComMExt.CAN_CommControlDeActivateTx
          OA_rpCSComMExt_CAN_CommControlDeActivateRx: operation=rpCSComMExt.CAN_CommControlDeActivateRx
          OA_rpCSComMExt_CAN_ActivateSilentCommunication: operation=rpCSComMExt.CAN_ActivateSilentCommunication
          OA_rpCSComMExt_CAN_CommControlActivateRx: operation=rpCSComMExt.CAN_CommControlActivateRx
          OA_rpCSComMExt_CAN_CommControlActivateTx: operation=rpCSComMExt.CAN_CommControlActivateTx
          OA_rpCSRxCanMdl_RxCan_GetSignalValueU8Arr: operation=rpCSRxCanMdl.RxCan_GetSignalValueU8Arr
          OA_rpCSRxCanMdl_RxCan_SetSignalInitValue: operation=rpCSRxCanMdl.RxCan_SetSignalInitValue
          OA_rpCSRxCanMdl_RxCan_SetSignalInitValueU8Arr: operation=rpCSRxCanMdl.RxCan_SetSignalInitValueU8Arr
          OA_rpCSRxCanMdl_RxCan_SignalInvalidProcessingControl: operation=rpCSRxCanMdl.RxCan_SignalInvalidProcessingControl
          OA_rpCSRxCanMdl_RxCan_SignalMissingProcessingControl: operation=rpCSRxCanMdl.RxCan_SignalMissingProcessingControl
          OA_rpCSRxCanMdl_RxCan_SignalNRProcessingControl: operation=rpCSRxCanMdl.RxCan_SignalNRProcessingControl
          OA_rpCSRxCanMdl_RxCan_SignalGetJustRcvdStatus: operation=rpCSRxCanMdl.RxCan_SignalGetJustRcvdStatus
          OA_rpCSRxCanMdl_RxCan_SignalClearJustRcvdStatus: operation=rpCSRxCanMdl.RxCan_SignalClearJustRcvdStatus
          OA_rpCSRxCanMdl_RxCan_GetSignalValue: operation=rpCSRxCanMdl.RxCan_GetSignalValue
          OA_rpCSTxCanMdl_TxCan_ClearCanSignalTxConfirmation: operation=rpCSTxCanMdl.TxCan_ClearCanSignalTxConfirmation
          OA_rpCSTxCanMdl_TxCan_GetCanSignalTxConfirmation: operation=rpCSTxCanMdl.TxCan_GetCanSignalTxConfirmation
          OA_rpCSTxCanMdl_TxCan_SetSignalFromRetentionBuffer: operation=rpCSTxCanMdl.TxCan_SetSignalFromRetentionBuffer
          OA_rpCSTxCanMdl_TxCan_SetSignalValue: operation=rpCSTxCanMdl.TxCan_SetSignalValue
          OA_rpCSTxCanMdl_TxCan_SetSignalValueU8Arr: operation=rpCSTxCanMdl.TxCan_SetSignalValueU8Arr
          OA_rpCS_RxCanMdlSafe_RxCan_GetSignalValueU8Arr: operation=rpCS_RxCanMdlSafe.RxCan_GetSignalValueU8Arr
          OA_rpCS_RxCanMdlSafe_RxCan_SetSignalInitValue: operation=rpCS_RxCanMdlSafe.RxCan_SetSignalInitValue
          OA_rpCS_RxCanMdlSafe_RxCan_SetSignalInitValueU8Arr: operation=rpCS_RxCanMdlSafe.RxCan_SetSignalInitValueU8Arr
          OA_rpCS_RxCanMdlSafe_RxCan_SignalInvalidProcessingControl: operation=rpCS_RxCanMdlSafe.RxCan_SignalInvalidProcessingControl
          OA_rpCS_RxCanMdlSafe_RxCan_SignalMissingProcessingControl: operation=rpCS_RxCanMdlSafe.RxCan_SignalMissingProcessingControl
          OA_rpCS_RxCanMdlSafe_RxCan_SignalNRProcessingControl: operation=rpCS_RxCanMdlSafe.RxCan_SignalNRProcessingControl
          OA_rpCS_RxCanMdlSafe_RxCan_SignalGetJustRcvdStatus: operation=rpCS_RxCanMdlSafe.RxCan_SignalGetJustRcvdStatus
          OA_rpCS_RxCanMdlSafe_RxCan_SignalClearJustRcvdStatus: operation=rpCS_RxCanMdlSafe.RxCan_SignalClearJustRcvdStatus
          OA_rpCS_RxCanMdlSafe_RxCan_GetSignalValue: operation=rpCS_RxCanMdlSafe.RxCan_GetSignalValue
          OA_rpCS_TxCanMdlSafe_TxCan_ClearCanSignalTxConfirmation: operation=rpCS_TxCanMdlSafe.TxCan_ClearCanSignalTxConfirmation
          OA_rpCS_TxCanMdlSafe_TxCan_GetCanSignalTxConfirmation: operation=rpCS_TxCanMdlSafe.TxCan_GetCanSignalTxConfirmation
          OA_rpCS_TxCanMdlSafe_TxCan_SetSignalFromRetentionBuffer: operation=rpCS_TxCanMdlSafe.TxCan_SetSignalFromRetentionBuffer
          OA_rpCS_TxCanMdlSafe_TxCan_SetSignalValue: operation=rpCS_TxCanMdlSafe.TxCan_SetSignalValue
          OA_rpCS_TxCanMdlSafe_TxCan_SetSignalValueU8Arr: operation=rpCS_TxCanMdlSafe.TxCan_SetSignalValueU8Arr
          OA_rp_CS_IoHwAb_Din_GetAsyncRawInput: operation=rp_CS_IoHwAb_Din.GetAsyncRawInput
          OA_rp_CS_IoHwAb_Din_GetProcessedInput: operation=rp_CS_IoHwAb_Din.GetProcessedInput
          OA_rp_CS_IoHwAb_Din_GetSyncRawInput: operation=rp_CS_IoHwAb_Din.GetSyncRawInput
          OA_rp_CS_IoHwAb_Din_GetInputGroup: operation=rp_CS_IoHwAb_Din.GetInputGroup
      runnable CComAbsCtrl_Impl_OnCommand: can-be-invoked-concurrently=true
  swc implementation IMPL_CComAbsCtrl: programming-language=C, behavior=IB_CComAbsCtrl
    code-descriptors:
      code CodeDescriptor
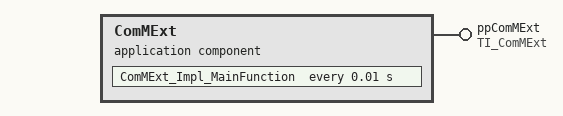
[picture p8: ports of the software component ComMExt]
  application sw component type ComMExt
    provide port ppComMExt: provided-interface=TI_ComMExt
      provided-com-specs:
        operation=CAN_ActivateSilentCommunication, queue-length=1
        operation=CAN_CommControlActivateRx, queue-length=1
        operation=CAN_CommControlActivateTx, queue-length=1
        operation=CAN_CommControlDeActivateRx, queue-length=1
        operation=CAN_CommControlDeActivateTx, queue-length=1
        operation=CAN_CommControlSetDone, queue-length=1
        operation=CAN_DeActivateSilentCommunication, queue-length=1
        operation=CAN_GetCurrentComMode, queue-length=1
        operation=CAN_ReleaseCommunication, queue-length=1
        operation=CAN_RequestCommunication, queue-length=1
        operation=GetBusOffStatus, queue-length=1
        operation=Get_MCAN_ERR_PIN_Status, queue-length=1
        operation=TI_ComMExt/Init, queue-length=1
    behavior IB_ComMExt: port-api-option{enable-take-address=false, indirect-api=false, port=ppComMExt}
      12 x operation invoked event:
        OIE_ppComMExt_ComMExt_CAN_ActivateSilentCommunicationTrigByCAN_ActivateSilentCommunication: start-on-event=ComMExt_CAN_ActivateSilentCommunication, operation=ppComMExt.CAN_ActivateSilentCommunication
        OIE_ppComMExt_ComMExt_CAN_CommControlActivateRxTrigByCAN_CommControlActivateRx: start-on-event=ComMExt_CAN_CommControlActivateRx, operation=ppComMExt.CAN_CommControlActivateRx
        OIE_ppComMExt_ComMExt_CAN_CommControlActivateTxTrigByCAN_CommControlActivateTx: start-on-event=ComMExt_CAN_CommControlActivateTx, operation=ppComMExt.CAN_CommControlActivateTx
        OIE_ppComMExt_ComMExt_CAN_CommControlDeActivateRxTrigByCAN_CommControlDeActivateRx: start-on-event=ComMExt_CAN_CommControlDeActivateRx, operation=ppComMExt.CAN_CommControlDeActivateRx
        OIE_ppComMExt_ComMExt_CAN_CommControlDeActivateTxTrigByCAN_CommControlDeActivateTx: start-on-event=ComMExt_CAN_CommControlDeActivateTx, operation=ppComMExt.CAN_CommControlDeActivateTx
        OIE_ppComMExt_ComMExt_CAN_CommControlSetDoneTrigByCAN_CommControlSetDone: start-on-event=ComMExt_CAN_CommControlSetDone, operation=ppComMExt.CAN_CommControlSetDone
        OIE_ppComMExt_ComMExt_CAN_DeActivateSilentCommunicationTrigByCAN_DeActivateSilentCommunication: start-on-event=ComMExt_CAN_DeActivateSilentCommunication, operation=ppComMExt.CAN_DeActivateSilentCommunication
        OIE_ppComMExt_ComMExt_CAN_GetCurrentComModeTrigByCAN_GetCurrentComMode: start-on-event=ComMExt_CAN_GetCurrentComMode, operation=ppComMExt.CAN_GetCurrentComMode
        OIE_ppComMExt_ComMExt_CAN_ReleaseCommunicationTrigByCAN_ReleaseCommunication: start-on-event=ComMExt_CAN_ReleaseCommunication, operation=ppComMExt.CAN_ReleaseCommunication
        OIE_ppComMExt_ComMExt_CAN_RequestCommunicationTrigByCAN_RequestCommunication: start-on-event=ComMExt_CAN_RequestCommunication, operation=ppComMExt.CAN_RequestCommunication
        OIE_ppComMExt_ComMExt_GetBusOffStatusTrigByGetBusOffStatus: start-on-event=ComMExt_GetBusOffStatus, operation=ppComMExt.GetBusOffStatus
        OIE_ppComMExt_ComMExt_Get_MCAN_ERR_PIN_StatusTrigByGet_MCAN_ERR_PIN_Status: start-on-event=ComMExt_Get_MCAN_ERR_PIN_Status, operation=ppComMExt.Get_MCAN_ERR_PIN_Status
      timing event TEComMExt_Impl_MainFunction: start-on-event=ComMExt_Impl_MainFunction, period=0.01
      operation invoked event OIE_ppComMExt_ComMExt_InitTrigByInit: start-on-event=ComMExt_Init, operation=ppComMExt.Init
      14 x runnable, all with can-be-invoked-concurrently=true:
        ComMExt_CAN_ActivateSilentCommunication
        ComMExt_CAN_CommControlActivateRx
        ComMExt_CAN_CommControlActivateTx
        ComMExt_CAN_CommControlDeActivateRx
        ComMExt_CAN_CommControlDeActivateTx
        ComMExt_CAN_CommControlSetDone
        ComMExt_CAN_DeActivateSilentCommunication
        ComMExt_CAN_GetCurrentComMode
        ComMExt_CAN_ReleaseCommunication
        ComMExt_CAN_RequestCommunication
        ComMExt_GetBusOffStatus
        ComMExt_Get_MCAN_ERR_PIN_Status
        ComMExt_Impl_MainFunction
        ComMExt_Init
  swc implementation IMPL_ComMExt: programming-language=C, behavior=IB_ComMExt
    code-descriptors:
      code CodeDescriptor
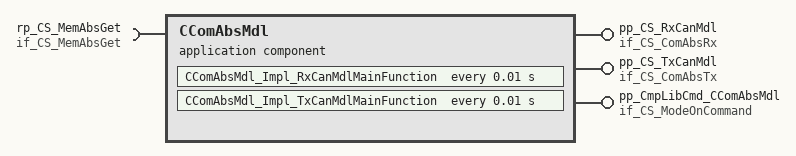
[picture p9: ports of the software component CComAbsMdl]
  application sw component type CComAbsMdl
    provide port pp_CS_RxCanMdl: provided-interface=if_CS_ComAbsRx
      provided-com-specs:
        operation=if_CS_ComAbsRx/RxCan_GetSignalValue, queue-length=1
        operation=if_CS_ComAbsRx/RxCan_GetSignalValueU8Arr, queue-length=1
        operation=if_CS_ComAbsRx/RxCan_SetSignalInitValue, queue-length=1
        operation=if_CS_ComAbsRx/RxCan_SetSignalInitValueU8Arr, queue-length=1
        operation=if_CS_ComAbsRx/RxCan_SignalClearJustRcvdStatus, queue-length=1
        operation=if_CS_ComAbsRx/RxCan_SignalGetJustRcvdStatus, queue-length=1
        operation=if_CS_ComAbsRx/RxCan_SignalInvalidProcessingControl, queue-length=1
        operation=if_CS_ComAbsRx/RxCan_SignalMissingProcessingControl, queue-length=1
        operation=if_CS_ComAbsRx/RxCan_SignalNRProcessingControl, queue-length=1
    provide port pp_CS_TxCanMdl: provided-interface=if_CS_ComAbsTx
      provided-com-specs:
        operation=if_CS_ComAbsTx/TxCan_ClearCanSignalTxConfirmation, queue-length=1
        operation=if_CS_ComAbsTx/TxCan_GetCanSignalTxConfirmation, queue-length=1
        operation=if_CS_ComAbsTx/TxCan_SetSignalFromRetentionBuffer, queue-length=1
        operation=if_CS_ComAbsTx/TxCan_SetSignalValue, queue-length=1
        operation=if_CS_ComAbsTx/TxCan_SetSignalValueU8Arr, queue-length=1
    provide port pp_CmpLibCmd_CComAbsMdl: server-com-spec{operation=Impl_OnCommand, queue-length=1}, provided-interface=if_CS_ModeOnCommand
    require port rp_CS_MemAbsGet: required-interface=if_CS_MemAbsGet
    behavior IB_CComAbsMdl
      operation invoked event OIE_pp_CmpLibCmd_CComAbsMdl_CComAbsMdl_Impl_OnCommandTrigByImpl_OnCommand: start-on-event=CComAbsMdl_Impl_OnCommand, operation=pp_CmpLibCmd_CComAbsMdl.Impl_OnCommand
      timing event TECComAbsMdl_Impl_RxCanMdlMainFunction: start-on-event=CComAbsMdl_Impl_RxCanMdlMainFunction, period=0.01
      timing event TECComAbsMdl_Impl_TxCanMdlMainFunction: start-on-event=CComAbsMdl_Impl_TxCanMdlMainFunction, period=0.01
      14 x operation invoked event:
        OIE_pp_CS_RxCanMdl_CComAbsMdl_RxCan_GetSignalValueTrigByRxCan_GetSignalValue: start-on-event=CComAbsMdl_RxCan_GetSignalValue, operation=pp_CS_RxCanMdl.RxCan_GetSignalValue
        OIE_pp_CS_RxCanMdl_CComAbsMdl_RxCan_GetSignalValueU8ArrTrigByRxCan_GetSignalValueU8Arr: start-on-event=CComAbsMdl_RxCan_GetSignalValueU8Arr, operation=pp_CS_RxCanMdl.RxCan_GetSignalValueU8Arr
        OIE_pp_CS_RxCanMdl_CComAbsMdl_RxCan_SetSignalInitValueTrigByRxCan_SetSignalInitValue: start-on-event=CComAbsMdl_RxCan_SetSignalInitValue, operation=pp_CS_RxCanMdl.RxCan_SetSignalInitValue
        OIE_pp_CS_RxCanMdl_CComAbsMdl_RxCan_SetSignalInitValueU8ArrTrigByRxCan_SetSignalInitValueU8Arr: start-on-event=CComAbsMdl_RxCan_SetSignalInitValueU8Arr, operation=pp_CS_RxCanMdl.RxCan_SetSignalInitValueU8Arr
        OIE_pp_CS_RxCanMdl_CComAbsMdl_RxCan_SignalClearJustRcvdStatusTrigByRxCan_SignalClearJustRcvdStatus: start-on-event=CComAbsMdl_RxCan_SignalClearJustRcvdStatus, operation=pp_CS_RxCanMdl.RxCan_SignalClearJustRcvdStatus
        OIE_pp_CS_RxCanMdl_CComAbsMdl_RxCan_SignalGetJustRcvdStatusTrigByRxCan_SignalGetJustRcvdStatus: start-on-event=CComAbsMdl_RxCan_SignalGetJustRcvdStatus, operation=pp_CS_RxCanMdl.RxCan_SignalGetJustRcvdStatus
        OIE_pp_CS_RxCanMdl_CComAbsMdl_RxCan_SignalInvalidProcessingControlTrigByRxCan_SignalInvalidProcessingControl: start-on-event=CComAbsMdl_RxCan_SignalInvalidProcessingControl, operation=pp_CS_RxCanMdl.RxCan_SignalInvalidProcessingControl
        OIE_pp_CS_RxCanMdl_CComAbsMdl_RxCan_SignalMissingProcessingControlTrigByRxCan_SignalMissingProcessingControl: start-on-event=CComAbsMdl_RxCan_SignalMissingProcessingControl, operation=pp_CS_RxCanMdl.RxCan_SignalMissingProcessingControl
        OIE_pp_CS_RxCanMdl_CComAbsMdl_RxCan_SignalNRProcessingControlTrigByRxCan_SignalNRProcessingControl: start-on-event=CComAbsMdl_RxCan_SignalNRProcessingControl, operation=pp_CS_RxCanMdl.RxCan_SignalNRProcessingControl
        OIE_pp_CS_TxCanMdl_CComAbsMdl_TxCan_ClearCanSignalTxConfirmationTrigByTxCan_ClearCanSignalTxConfirmation: start-on-event=CComAbsMdl_TxCan_ClearCanSignalTxConfirmation, operation=pp_CS_TxCanMdl.TxCan_ClearCanSignalTxConfirmation
        OIE_pp_CS_TxCanMdl_CComAbsMdl_TxCan_GetCanSignalTxConfirmationTrigByTxCan_GetCanSignalTxConfirmation: start-on-event=CComAbsMdl_TxCan_GetCanSignalTxConfirmation, operation=pp_CS_TxCanMdl.TxCan_GetCanSignalTxConfirmation
        OIE_pp_CS_TxCanMdl_CComAbsMdl_TxCan_SetSignalFromRetentionBufferTrigByTxCan_SetSignalFromRetentionBuffer: start-on-event=CComAbsMdl_TxCan_SetSignalFromRetentionBuffer, operation=pp_CS_TxCanMdl.TxCan_SetSignalFromRetentionBuffer
        OIE_pp_CS_TxCanMdl_CComAbsMdl_TxCan_SetSignalValueTrigByTxCan_SetSignalValue: start-on-event=CComAbsMdl_TxCan_SetSignalValue, operation=pp_CS_TxCanMdl.TxCan_SetSignalValue
        OIE_pp_CS_TxCanMdl_CComAbsMdl_TxCan_SetSignalValueU8ArrTrigByTxCan_SetSignalValueU8Arr: start-on-event=CComAbsMdl_TxCan_SetSignalValueU8Arr, operation=pp_CS_TxCanMdl.TxCan_SetSignalValueU8Arr
      port-api-options:
        enable-take-address=false, indirect-api=false, port=pp_CS_RxCanMdl
        enable-take-address=false, indirect-api=false, port=pp_CS_TxCanMdl
        enable-take-address=false, indirect-api=false, port=pp_CmpLibCmd_CComAbsMdl
        enable-take-address=false, indirect-api=false, port=CComAbsMdl/rp_CS_MemAbsGet
      17 x runnable, all with can-be-invoked-concurrently=true:
        CComAbsMdl_Impl_OnCommand
        CComAbsMdl_Impl_RxCanMdlMainFunction
          94 x sync call, all with timeout=0.0:
            OA_rp_CS_MemAbsGet_Get_BsShare_SwUpdReflash_Element: operation=rp_CS_MemAbsGet.Get_BsShare_SwUpdReflash_Element
            OA_rp_CS_MemAbsGet_Get_BsShare_SwUpdFotaMode_Element: operation=rp_CS_MemAbsGet.Get_BsShare_SwUpdFotaMode_Element
            OA_rp_CS_MemAbsGet_Get_BsShare_SwUpdFotaFinPrint_Element: operation=rp_CS_MemAbsGet.Get_BsShare_SwUpdFotaFinPrint_Element
            OA_rp_CS_MemAbsGet_Get_BsShare_SwUpdFotaStatus_Element: operation=rp_CS_MemAbsGet.Get_BsShare_SwUpdFotaStatus_Element
            OA_rp_CS_MemAbsGet_Get_BsShare_SwUpdFotadecrypt_Element: operation=rp_CS_MemAbsGet.Get_BsShare_SwUpdFotadecrypt_Element
            OA_rp_CS_MemAbsGet_Get_BsShare_EcuPartNumber_Element: operation=rp_CS_MemAbsGet.Get_BsShare_EcuPartNumber_Element
            OA_rp_CS_MemAbsGet_Get_BsShare_VisteonPartNumber: operation=rp_CS_MemAbsGet.Get_BsShare_VisteonPartNumber
            OA_rp_CS_MemAbsGet_Get_BsShare_VisteonPCBPartNumber: operation=rp_CS_MemAbsGet.Get_BsShare_VisteonPCBPartNumber
            OA_rp_CS_MemAbsGet_Get_BsShare_ProductSerialNumber: operation=rp_CS_MemAbsGet.Get_BsShare_ProductSerialNumber
            OA_rp_CS_MemAbsGet_Get_BsShare_PCBSerialNumber: operation=rp_CS_MemAbsGet.Get_BsShare_PCBSerialNumber
            OA_rp_CS_MemAbsGet_Get_BsShare_SMTManufacturingDate: operation=rp_CS_MemAbsGet.Get_BsShare_SMTManufacturingDate
            OA_rp_CS_MemAbsGet_Get_BsShare_AssemblyManufacturingDate: operation=rp_CS_MemAbsGet.Get_BsShare_AssemblyManufacturingDate
            OA_rp_CS_MemAbsGet_Get_BsShare_SMTPlantNumber: operation=rp_CS_MemAbsGet.Get_BsShare_SMTPlantNumber
            OA_rp_CS_MemAbsGet_Get_BsShare_AssemblyPlantNumber: operation=rp_CS_MemAbsGet.Get_BsShare_AssemblyPlantNumber
            OA_rp_CS_MemAbsGet_Get_BsShare_HWModification: operation=rp_CS_MemAbsGet.Get_BsShare_HWModification
            OA_rp_CS_MemAbsGet_Get_BsShare_VisMeet_Element: operation=rp_CS_MemAbsGet.Get_BsShare_VisMeet_Element
            OA_rp_CS_MemAbsGet_Get_BsShare_VisMeet_EOLEntry_Element: operation=rp_CS_MemAbsGet.Get_BsShare_VisMeet_EOLEntry_Element
            OA_rp_CS_MemAbsGet_Get_BsShare_VehicleConfig_Element: operation=rp_CS_MemAbsGet.Get_BsShare_VehicleConfig_Element
            OA_rp_CS_MemAbsGet_Get_BsConst_SpeedoGauge_Element: operation=rp_CS_MemAbsGet.Get_BsConst_SpeedoGauge_Element
            OA_rp_CS_MemAbsGet_Get_BsConst_TachoGauge_Element: operation=rp_CS_MemAbsGet.Get_BsConst_TachoGauge_Element
            OA_rp_CS_MemAbsGet_Get_BsConst_FuelGauge_Element: operation=rp_CS_MemAbsGet.Get_BsConst_FuelGauge_Element
            OA_rp_CS_MemAbsGet_Get_BsConst_TempGauge_Element: operation=rp_CS_MemAbsGet.Get_BsConst_TempGauge_Element
            OA_rp_CS_MemAbsGet_Get_BsConst_PowerGauge_Element: operation=rp_CS_MemAbsGet.Get_BsConst_PowerGauge_Element
            OA_rp_CS_MemAbsGet_Get_BsConst_OilGauge_Element: operation=rp_CS_MemAbsGet.Get_BsConst_OilGauge_Element
            OA_rp_CS_MemAbsGet_Get_BsConst_TripComputer_Element: operation=rp_CS_MemAbsGet.Get_BsConst_TripComputer_Element
            OA_rp_CS_MemAbsGet_Get_BsConst_Compensation_Line_Slope_m: operation=rp_CS_MemAbsGet.Get_BsConst_Compensation_Line_Slope_m
            OA_rp_CS_MemAbsGet_Get_BsConst_Compensation_Line_Shift_b: operation=rp_CS_MemAbsGet.Get_BsConst_Compensation_Line_Shift_b
            OA_rp_CS_MemAbsGet_Get_BsConst_Lookup_Curve_HotSpot_Coef_X: operation=rp_CS_MemAbsGet.Get_BsConst_Lookup_Curve_HotSpot_Coef_X
            OA_rp_CS_MemAbsGet_Get_BsConst_Lookup_Curve_HotSpot_Coef_Y: operation=rp_CS_MemAbsGet.Get_BsConst_Lookup_Curve_HotSpot_Coef_Y
            OA_rp_CS_MemAbsGet_Get_BsConst_Temp_Threshold_Hysteresis_Derating: operation=rp_CS_MemAbsGet.Get_BsConst_Temp_Threshold_Hysteresis_Derating
            OA_rp_CS_MemAbsGet_Get_BsConst_Derating_Backlight_Disable: operation=rp_CS_MemAbsGet.Get_BsConst_Derating_Backlight_Disable
            OA_rp_CS_MemAbsGet_Get_BsConst_Temperature_Sensor_Conv: operation=rp_CS_MemAbsGet.Get_BsConst_Temperature_Sensor_Conv
            OA_rp_CS_MemAbsGet_Get_BsConst_PCB_Temperature_Sensor_Conv: operation=rp_CS_MemAbsGet.Get_BsConst_PCB_Temperature_Sensor_Conv
            OA_rp_CS_MemAbsGet_Get_BsConst_Display_Illum_Max_Level: operation=rp_CS_MemAbsGet.Get_BsConst_Display_Illum_Max_Level
            OA_rp_CS_MemAbsGet_Get_BsConst_PWM_boost_bypass_duty: operation=rp_CS_MemAbsGet.Get_BsConst_PWM_boost_bypass_duty
            OA_rp_CS_MemAbsGet_Get_BsConst_BsConst_Illumination_ReservedByte: operation=rp_CS_MemAbsGet.Get_BsConst_BsConst_Illumination_ReservedByte
            OA_rp_CS_MemAbsGet_Get_BsConst_Compensation_Line_Slope_m_SafeCopy1: operation=rp_CS_MemAbsGet.Get_BsConst_Compensation_Line_Slope_m_SafeCopy1
            OA_rp_CS_MemAbsGet_Get_BsConst_Compensation_Line_Shift_b_SafeCopy1: operation=rp_CS_MemAbsGet.Get_BsConst_Compensation_Line_Shift_b_SafeCopy1
            OA_rp_CS_MemAbsGet_Get_BsConst_Lookup_Curve_HotSpot_Coef_X_SafeCopy1: operation=rp_CS_MemAbsGet.Get_BsConst_Lookup_Curve_HotSpot_Coef_X_SafeCopy1
            OA_rp_CS_MemAbsGet_Get_BsConst_Lookup_Curve_HotSpot_Coef_Y_SafeCopy1: operation=rp_CS_MemAbsGet.Get_BsConst_Lookup_Curve_HotSpot_Coef_Y_SafeCopy1
            OA_rp_CS_MemAbsGet_Get_BsConst_Temp_Threshold_Hysteresis_Derating_SafeCopy1: operation=rp_CS_MemAbsGet.Get_BsConst_Temp_Threshold_Hysteresis_Derating_SafeCopy1
            OA_rp_CS_MemAbsGet_Get_BsConst_Derating_Backlight_Disable_SafeCopy1: operation=rp_CS_MemAbsGet.Get_BsConst_Derating_Backlight_Disable_SafeCopy1
            OA_rp_CS_MemAbsGet_Get_BsConst_Temperature_Sensor_Conv_SafeCopy1: operation=rp_CS_MemAbsGet.Get_BsConst_Temperature_Sensor_Conv_SafeCopy1
            OA_rp_CS_MemAbsGet_Get_BsConst_PCB_Temperature_Sensor_Conv_SafeCopy1: operation=rp_CS_MemAbsGet.Get_BsConst_PCB_Temperature_Sensor_Conv_SafeCopy1
            OA_rp_CS_MemAbsGet_Get_BsConst_Display_Illum_Max_Level_SafeCopy1: operation=rp_CS_MemAbsGet.Get_BsConst_Display_Illum_Max_Level_SafeCopy1
            OA_rp_CS_MemAbsGet_Get_BsConst_PWM_boost_bypass_duty_SafeCopy1: operation=rp_CS_MemAbsGet.Get_BsConst_PWM_boost_bypass_duty_SafeCopy1
            OA_rp_CS_MemAbsGet_Get_BsConst_BsConst_Illumination_ReservedByte_SafeCopy1: operation=rp_CS_MemAbsGet.Get_BsConst_BsConst_Illumination_ReservedByte_SafeCopy1
            OA_rp_CS_MemAbsGet_Get_BsConst_Compensation_Line_Slope_m_SafeCopy2: operation=rp_CS_MemAbsGet.Get_BsConst_Compensation_Line_Slope_m_SafeCopy2
            OA_rp_CS_MemAbsGet_Get_BsConst_Compensation_Line_Shift_b_SafeCopy2: operation=rp_CS_MemAbsGet.Get_BsConst_Compensation_Line_Shift_b_SafeCopy2
            OA_rp_CS_MemAbsGet_Get_BsConst_Lookup_Curve_HotSpot_Coef_X_SafeCopy2: operation=rp_CS_MemAbsGet.Get_BsConst_Lookup_Curve_HotSpot_Coef_X_SafeCopy2
            OA_rp_CS_MemAbsGet_Get_BsConst_Lookup_Curve_HotSpot_Coef_Y_SafeCopy2: operation=rp_CS_MemAbsGet.Get_BsConst_Lookup_Curve_HotSpot_Coef_Y_SafeCopy2
            OA_rp_CS_MemAbsGet_Get_BsConst_Temp_Threshold_Hysteresis_Derating_SafeCopy2: operation=rp_CS_MemAbsGet.Get_BsConst_Temp_Threshold_Hysteresis_Derating_SafeCopy2
            OA_rp_CS_MemAbsGet_Get_BsConst_Derating_Backlight_Disable_SafeCopy2: operation=rp_CS_MemAbsGet.Get_BsConst_Derating_Backlight_Disable_SafeCopy2
            OA_rp_CS_MemAbsGet_Get_BsConst_Temperature_Sensor_Conv_SafeCopy2: operation=rp_CS_MemAbsGet.Get_BsConst_Temperature_Sensor_Conv_SafeCopy2
            OA_rp_CS_MemAbsGet_Get_BsConst_PCB_Temperature_Sensor_Conv_SafeCopy2: operation=rp_CS_MemAbsGet.Get_BsConst_PCB_Temperature_Sensor_Conv_SafeCopy2
            OA_rp_CS_MemAbsGet_Get_BsConst_Display_Illum_Max_Level_SafeCopy2: operation=rp_CS_MemAbsGet.Get_BsConst_Display_Illum_Max_Level_SafeCopy2
            OA_rp_CS_MemAbsGet_Get_BsConst_PWM_boost_bypass_duty_SafeCopy2: operation=rp_CS_MemAbsGet.Get_BsConst_PWM_boost_bypass_duty_SafeCopy2
            OA_rp_CS_MemAbsGet_Get_BsConst_BsConst_Illumination_ReservedByte_SafeCopy2: operation=rp_CS_MemAbsGet.Get_BsConst_BsConst_Illumination_ReservedByte_SafeCopy2
            OA_rp_CS_MemAbsGet_Get_BsConst_Audio_Element: operation=rp_CS_MemAbsGet.Get_BsConst_Audio_Element
            OA_rp_CS_MemAbsGet_Get_BsConst_Warning_Element: operation=rp_CS_MemAbsGet.Get_BsConst_Warning_Element
            OA_rp_CS_MemAbsGet_Get_BsConst_RealTimeClock_Element: operation=rp_CS_MemAbsGet.Get_BsConst_RealTimeClock_Element
            OA_rp_CS_MemAbsGet_Get_BsConst_Communication_Element: operation=rp_CS_MemAbsGet.Get_BsConst_Communication_Element
            OA_rp_CS_MemAbsGet_Get_BsConst_Power_Element: operation=rp_CS_MemAbsGet.Get_BsConst_Power_Element
            OA_rp_CS_MemAbsGet_Get_BsConst_ServiceReminder_Element: operation=rp_CS_MemAbsGet.Get_BsConst_ServiceReminder_Element
            OA_rp_CS_MemAbsGet_Get_BsConst_EngOffTimer_Element: operation=rp_CS_MemAbsGet.Get_BsConst_EngOffTimer_Element
            OA_rp_CS_MemAbsGet_Get_BsCys_Certicificate_Element: operation=rp_CS_MemAbsGet.Get_BsCys_Certicificate_Element
            OA_rp_CS_MemAbsGet_Get_RefCys_Certicificate_Element: operation=rp_CS_MemAbsGet.Get_RefCys_Certicificate_Element
            OA_rp_CS_MemAbsGet_Get_RefCys_Certicificate1_Element: operation=rp_CS_MemAbsGet.Get_RefCys_Certicificate1_Element
            OA_rp_CS_MemAbsGet_Get_BsRt_Odometer_Element: operation=rp_CS_MemAbsGet.Get_BsRt_Odometer_Element
            OA_rp_CS_MemAbsGet_Get_BsRt_SpeedoGauge_Element: operation=rp_CS_MemAbsGet.Get_BsRt_SpeedoGauge_Element
            OA_rp_CS_MemAbsGet_Get_BsRt_TachoGauge_Element: operation=rp_CS_MemAbsGet.Get_BsRt_TachoGauge_Element
            OA_rp_CS_MemAbsGet_Get_BsRt_FuelGauge_Element: operation=rp_CS_MemAbsGet.Get_BsRt_FuelGauge_Element
            OA_rp_CS_MemAbsGet_Get_BsRt_TempGauge_Element: operation=rp_CS_MemAbsGet.Get_BsRt_TempGauge_Element
            OA_rp_CS_MemAbsGet_Get_BsRt_PowerGauge_Element: operation=rp_CS_MemAbsGet.Get_BsRt_PowerGauge_Element
            OA_rp_CS_MemAbsGet_Get_BsRt_OilGauge_Element: operation=rp_CS_MemAbsGet.Get_BsRt_OilGauge_Element
            OA_rp_CS_MemAbsGet_Get_BsRt_TripComputer_Element: operation=rp_CS_MemAbsGet.Get_BsRt_TripComputer_Element
            OA_rp_CS_MemAbsGet_Get_BsRt_Warning_Element: operation=rp_CS_MemAbsGet.Get_BsRt_Warning_Element
            OA_rp_CS_MemAbsGet_Get_BsRt_RealTimeClock_Element: operation=rp_CS_MemAbsGet.Get_BsRt_RealTimeClock_Element
            OA_rp_CS_MemAbsGet_Get_BsRt_Personalization_Element: operation=rp_CS_MemAbsGet.Get_BsRt_Personalization_Element
            OA_rp_CS_MemAbsGet_Get_BsRt_Illumination_Element: operation=rp_CS_MemAbsGet.Get_BsRt_Illumination_Element
            OA_rp_CS_MemAbsGet_Get_BsRt_CusDlt_Element: operation=rp_CS_MemAbsGet.Get_BsRt_CusDlt_Element
            OA_rp_CS_MemAbsGet_Get_BsReten_Odometer_Element: operation=rp_CS_MemAbsGet.Get_BsReten_Odometer_Element
            OA_rp_CS_MemAbsGet_Get_BsReten_Gauges_Element: operation=rp_CS_MemAbsGet.Get_BsReten_Gauges_Element
            OA_rp_CS_MemAbsGet_Get_BsReten_Tripcomputer_Element: operation=rp_CS_MemAbsGet.Get_BsReten_Tripcomputer_Element
            OA_rp_CS_MemAbsGet_Get_BsReten_Illumination_Element: operation=rp_CS_MemAbsGet.Get_BsReten_Illumination_Element
            OA_rp_CS_MemAbsGet_Get_BsReten_Audio_Element: operation=rp_CS_MemAbsGet.Get_BsReten_Audio_Element
            OA_rp_CS_MemAbsGet_Get_BsReten_Warning_Element: operation=rp_CS_MemAbsGet.Get_BsReten_Warning_Element
            OA_rp_CS_MemAbsGet_Get_BsReten_RealTimeClock_Element: operation=rp_CS_MemAbsGet.Get_BsReten_RealTimeClock_Element
            OA_rp_CS_MemAbsGet_Get_BsReten_Communication_Element: operation=rp_CS_MemAbsGet.Get_BsReten_Communication_Element
            OA_rp_CS_MemAbsGet_Get_BsReten_Personalization_Element: operation=rp_CS_MemAbsGet.Get_BsReten_Personalization_Element
            OA_rp_CS_MemAbsGet_Get_BsReten_Power_Element: operation=rp_CS_MemAbsGet.Get_BsReten_Power_Element
            OA_rp_CS_MemAbsGet_Get_BsReten_Display_Element: operation=rp_CS_MemAbsGet.Get_BsReten_Display_Element
            OA_rp_CS_MemAbsGet_Get_BsDiag_ErrorRecord_Element: operation=rp_CS_MemAbsGet.Get_BsDiag_ErrorRecord_Element
            OA_rp_CS_MemAbsGet_Get_BsDiag_Dtc_Element: operation=rp_CS_MemAbsGet.Get_BsDiag_Dtc_Element
        CComAbsMdl_Impl_TxCanMdlMainFunction
        CComAbsMdl_RxCan_GetSignalValue
        CComAbsMdl_RxCan_GetSignalValueU8Arr
        CComAbsMdl_RxCan_SetSignalInitValue
        CComAbsMdl_RxCan_SetSignalInitValueU8Arr
        CComAbsMdl_RxCan_SignalClearJustRcvdStatus
        CComAbsMdl_RxCan_SignalGetJustRcvdStatus
        CComAbsMdl_RxCan_SignalInvalidProcessingControl
        CComAbsMdl_RxCan_SignalMissingProcessingControl
        CComAbsMdl_RxCan_SignalNRProcessingControl
        CComAbsMdl_TxCan_ClearCanSignalTxConfirmation
        CComAbsMdl_TxCan_GetCanSignalTxConfirmation
        CComAbsMdl_TxCan_SetSignalFromRetentionBuffer
        CComAbsMdl_TxCan_SetSignalValue
        CComAbsMdl_TxCan_SetSignalValueU8Arr
  swc implementation IMPL_CComAbsMdl: programming-language=C, behavior=IB_CComAbsMdl
    code-descriptors:
      code CodeDescriptor
